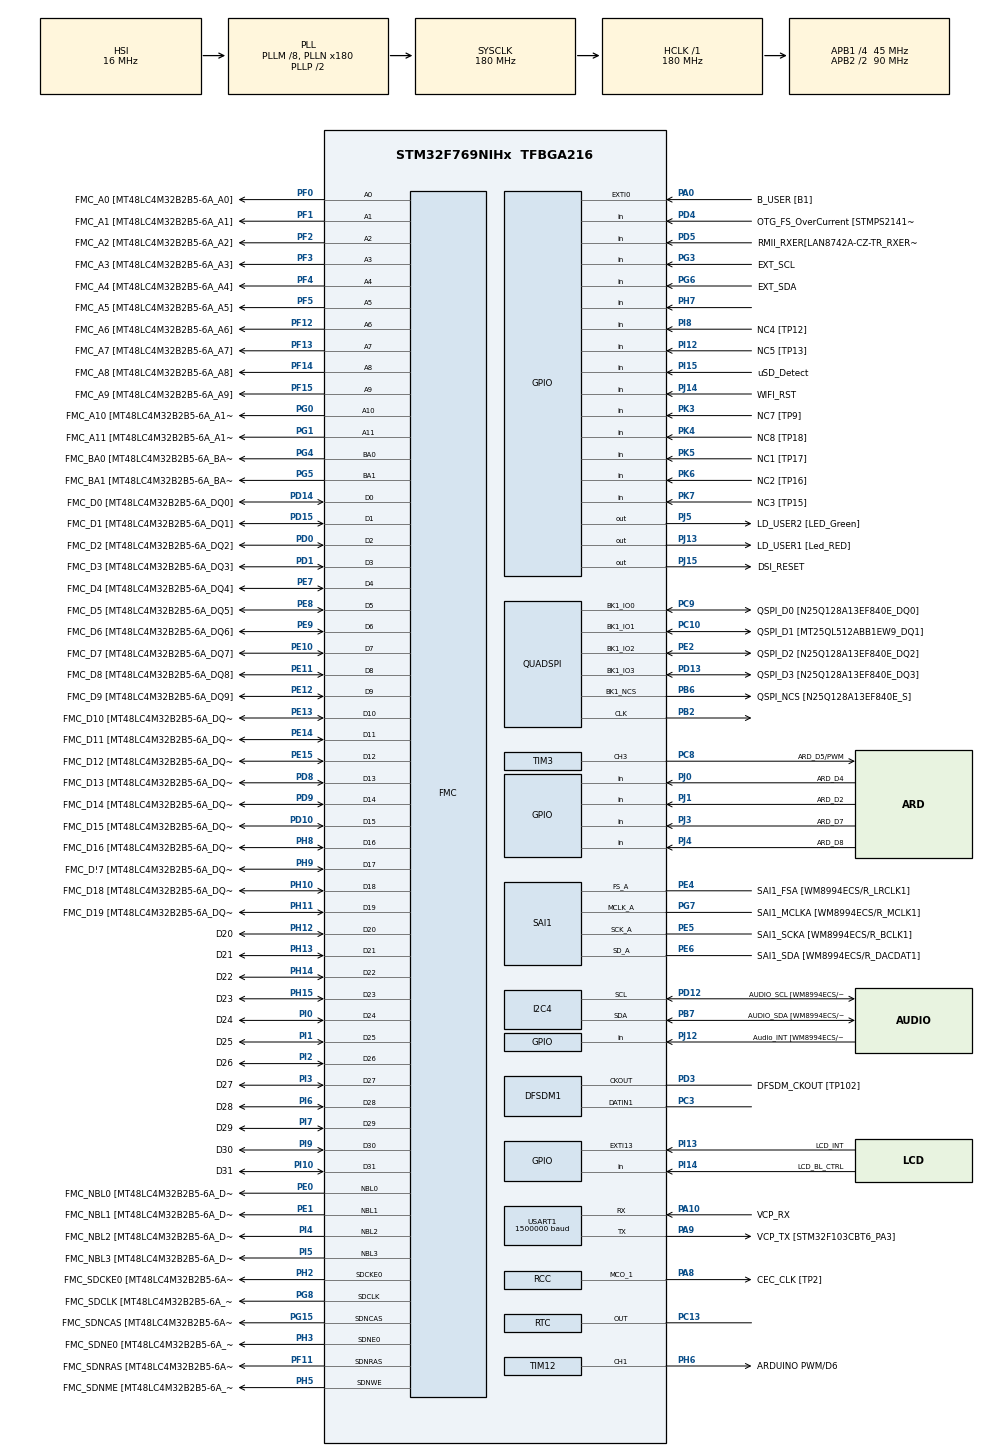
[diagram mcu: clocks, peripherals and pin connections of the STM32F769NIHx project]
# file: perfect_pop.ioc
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CORTEX_M7.AccessPermission-Cortex_Memory_Protection_Unit_Region0_Settings=MPU_REGION_FULL_ACCESS
CORTEX_M7.BaseAddress-Cortex_Memory_Protection_Unit_Region0_Settings=0xC0000000
CORTEX_M7.DisableExec-Cortex_Memory_Protection_Unit_Region0_Settings=MPU_INSTRUCTION_ACCESS_DISABLE
CORTEX_M7.Enable-Cortex_Memory_Protection_Unit_Region0_Settings=MPU_REGION_ENABLE
CORTEX_M7.MPU_Control=MPU_HFNMI_PRIVDEF
CORTEX_M7.Size-Cortex_Memory_Protection_Unit_Region0_Settings=MPU_REGION_SIZE_2MB
DFSDM1.Divider=75
DFSDM1.DmaMode_inj_FIL0=ENABLE
DFSDM1.DmaMode_reg_FIL0=ENABLE
DFSDM1.FastMode_reg_FIL0=ENABLE
DFSDM1.FilterOrder_CH0=DFSDM_CHANNEL_FASTSINC_ORDER
DFSDM1.Filter_injChannel0_FIL0=DFSDM_CHANNEL_0
DFSDM1.Filter_regChannel_FIL0=DFSDM_CHANNEL_0
DFSDM1.Fosr_FIL0=50
DFSDM1.Iosr_FIL0=1
DFSDM1.Offset_CH0=0
DFSDM1.Oversampling_CH0=1
DFSDM1.RightBitShift_CH0=0
DFSDM1.ScanMode_inj_FIL0=ENABLE
DFSDM1.Selection=DFSDM_CHANNEL_OUTPUT_CLOCK_SYSTEM
DFSDM1.SincOrder_FIL0=DFSDM_FILTER_SINC3_ORDER
DFSDM1.Trigger_inj_FIL0=DFSDM_FILTER_SW_TRIGGER
DFSDM1.Type_spi_CH0=DFSDM_CHANNEL_SPI_FALLING
DSIHOST.CommandSize=800
DSIHOST.NumberOfLanes=DSI_TWO_DATA_LANES
DSIHOST.StopWaitTime=10
DSIHOST_CKN.GPIO_Label=DSI_CK_N
DSIHOST_CKN.Mode=DSIHost_Adapted
DSIHOST_CKN.Signal=DSIHOST_CKN
DSIHOST_CKP.GPIO_Label=DSI_CK_P
DSIHOST_CKP.Mode=DSIHost_Adapted
DSIHOST_CKP.Signal=DSIHOST_CKP
DSIHOST_D0N.GPIO_Label=DSI_D0_N
DSIHOST_D0N.Mode=DSIHost_Adapted
DSIHOST_D0N.Signal=DSIHOST_D0N
DSIHOST_D0P.GPIO_Label=DSI_D0_p
DSIHOST_D0P.Mode=DSIHost_Adapted
DSIHOST_D0P.Signal=DSIHOST_D0P
DSIHOST_D1N.GPIO_Label=DSI_D1_N
DSIHOST_D1N.Mode=DSIHost_Adapted
DSIHOST_D1N.Signal=DSIHOST_D1N
DSIHOST_D1P.GPIO_Label=DSI_D1_P
DSIHOST_D1P.Mode=DSIHost_Adapted
DSIHOST_D1P.Signal=DSIHOST_D1P
Dma.DFSDM1_FLT0.0.Direction=DMA_PERIPH_TO_MEMORY
Dma.DFSDM1_FLT0.0.FIFOMode=DMA_FIFOMODE_DISABLE
Dma.DFSDM1_FLT0.0.Instance=DMA2_Stream0
Dma.DFSDM1_FLT0.0.MemDataAlignment=DMA_MDATAALIGN_WORD
Dma.DFSDM1_FLT0.0.MemInc=DMA_MINC_ENABLE
Dma.DFSDM1_FLT0.0.Mode=DMA_CIRCULAR
Dma.DFSDM1_FLT0.0.PeriphDataAlignment=DMA_PDATAALIGN_WORD
Dma.DFSDM1_FLT0.0.PeriphInc=DMA_PINC_DISABLE
Dma.DFSDM1_FLT0.0.Priority=DMA_PRIORITY_MEDIUM
Dma.Request0=DFSDM1_FLT0
Dma.Request1=USART1_RX
Dma.Request2=USART1_TX
Dma.Request3=SAI1_A
Dma.SAI1_A.3.Direction=DMA_MEMORY_TO_PERIPH
Dma.SAI1_A.3.FIFOMode=DMA_FIFOMODE_DISABLE
Dma.SAI1_A.3.Instance=DMA2_Stream1
Dma.SAI1_A.3.MemDataAlignment=DMA_MDATAALIGN_HALFWORD
Dma.SAI1_A.3.MemInc=DMA_MINC_DISABLE
Dma.SAI1_A.3.Mode=DMA_CIRCULAR
Dma.SAI1_A.3.PeriphDataAlignment=DMA_PDATAALIGN_HALFWORD
Dma.SAI1_A.3.PeriphInc=DMA_PINC_DISABLE
Dma.SAI1_A.3.Priority=DMA_PRIORITY_HIGH
Dma.USART1_RX.1.Direction=DMA_PERIPH_TO_MEMORY
Dma.USART1_RX.1.FIFOMode=DMA_FIFOMODE_DISABLE
Dma.USART1_RX.1.Instance=DMA2_Stream2
Dma.USART1_RX.1.MemDataAlignment=DMA_MDATAALIGN_BYTE
Dma.USART1_RX.1.MemInc=DMA_MINC_ENABLE
Dma.USART1_RX.1.Mode=DMA_CIRCULAR
Dma.USART1_RX.1.PeriphDataAlignment=DMA_PDATAALIGN_BYTE
Dma.USART1_RX.1.PeriphInc=DMA_PINC_DISABLE
Dma.USART1_RX.1.Priority=DMA_PRIORITY_LOW
Dma.USART1_TX.2.Direction=DMA_MEMORY_TO_PERIPH
Dma.USART1_TX.2.FIFOMode=DMA_FIFOMODE_DISABLE
Dma.USART1_TX.2.Instance=DMA2_Stream7
Dma.USART1_TX.2.MemDataAlignment=DMA_MDATAALIGN_BYTE
Dma.USART1_TX.2.MemInc=DMA_MINC_ENABLE
Dma.USART1_TX.2.Mode=DMA_NORMAL
Dma.USART1_TX.2.PeriphDataAlignment=DMA_PDATAALIGN_BYTE
Dma.USART1_TX.2.PeriphInc=DMA_PINC_DISABLE
Dma.USART1_TX.2.Priority=DMA_PRIORITY_LOW
FMC.CASLatency1=FMC_SDRAM_CAS_LATENCY_3
FMC.ExitSelfRefreshDelay1=7
FMC.LoadToActiveDelay1=2
FMC.RPDelay1=2
FMC.RPDelay2=2
FMC.ReadBurst1=FMC_SDRAM_RBURST_ENABLE
FMC.ReadBurst2=FMC_SDRAM_RBURST_ENABLE
FMC.RowCycleDelay1=7
FMC.RowCycleDelay2=7
FMC.SDClockPeriod1=FMC_SDRAM_CLOCK_PERIOD_2
FMC.SDClockPeriod2=FMC_SDRAM_CLOCK_PERIOD_2
FMC.SelfRefreshTime1=4
FMC.WriteRecoveryTime1=2
FREERTOS.Tasks01=defaultTask,24,128,StartDefaultTask,Default,NULL,Dynamic,NULL,NULL;audio_producer,31,1280,start_audio_producer,Default,NULL,Dynamic,NULL,NULL;uart_handler,8,128,start_uart_handler,Default,NULL,Dynamic,NULL,NULL;audio_filter,31,1280,start_audio_filter,Default,NULL,Dynamic,NULL,NULL;display_control,23,2048,start_display_control,Default,NULL,Dynamic,NULL,NULL
FREERTOS.configCHECK_FOR_STACK_OVERFLOW=2
FREERTOS.configTOTAL_HEAP_SIZE=24576
FREERTOS.configUSE_MALLOC_FAILED_HOOK=1
FREERTOS.configUSE_NEWLIB_REENTRANT=1
I2C4.Timing=0xC0000E12
LTDC.ActiveW=800
LTDC.Alpha_L0=255
LTDC.BlendingFactor1_L0=LTDC_BLENDING_FACTOR1_PAxCA
LTDC.BlendingFactor2_L0=LTDC_BLENDING_FACTOR2_PAxCA
LTDC.FBStartAdress_L0=0xC0000000
LTDC.HBP=1
LTDC.HFP=1
LTDC.HSync=1
LTDC.ImageHeight_L0=480
LTDC.ImageWidth_L0=800
LTDC.Layers=0
LTDC.PixelFormat_L0=LTDC_PIXEL_FORMAT_ARGB8888
LTDC.VBP=1
LTDC.VFP=1
LTDC.VSync=1
LTDC.WindowX1_L0=800
LTDC.WindowY1_L0=480
Mcu.Family=STM32F7
Mcu.Name=STM32F769NIHx
Mcu.Package=TFBGA216
NVIC.DFSDM1_FLT0_IRQn=true\:5\:0\:false\:false\:true\:true\:true\:true\:true
NVIC.DMA2_Stream0_IRQn=true\:5\:0\:false\:false\:true\:false\:false\:true\:true
NVIC.DMA2_Stream1_IRQn=true\:5\:0\:false\:false\:true\:true\:false\:true\:true
NVIC.DMA2_Stream2_IRQn=true\:5\:0\:false\:false\:true\:true\:false\:true\:true
NVIC.DMA2_Stream7_IRQn=true\:5\:0\:false\:false\:true\:true\:false\:true\:true
NVIC.I2C4_ER_IRQn=true\:5\:0\:false\:false\:true\:true\:true\:true\:true
NVIC.I2C4_EV_IRQn=true\:5\:0\:false\:false\:true\:true\:true\:true\:true
NVIC.LTDC_IRQn=true\:5\:0\:false\:false\:true\:true\:true\:true\:true
NVIC.PriorityGroup=NVIC_PRIORITYGROUP_4
NVIC.SAI1_IRQn=true\:5\:0\:false\:false\:true\:true\:true\:true\:true
NVIC.TIM6_DAC_IRQn=true\:15\:0\:false\:false\:true\:false\:false\:true\:true
NVIC.TimeBase=TIM6_DAC_IRQn
NVIC.TimeBaseIP=TIM6
NVIC.USART1_IRQn=true\:5\:0\:false\:false\:true\:true\:true\:true\:true
PA0/WKUP.GPIO_Label=B_USER [B1]
PA0/WKUP.Signal=GPXTI0
PA1.GPIO_Label=RMII_REF_CLK [LAN8742A-CZ-TR_REFCLK0]
PA1.Signal=ETH_REF_CLK
PA10.GPIO_Label=VCP_RX 
PA10.Mode=Asynchronous
PA10.Signal=USART1_RX
PA11.GPIO_Label=SPI2_NSS
PA11.Signal=SPI2_NSS
PA12.GPIO_Label=ARD_D13/SCK
PA12.GPIO_Mode=GPIO_MODE_AF_PP
PA12.GPIO_PuPd=GPIO_NOPULL
PA12.GPIO_Speed=GPIO_SPEED_FREQ_LOW
PA12.Signal=SPI2_SCK
PA13.GPIO_Label=SWDIO
PA13.Mode=Serial_Wire
PA13.Signal=SYS_JTMS-SWDIO
PA14.GPIO_Label=SWCLK
PA14.Mode=Serial_Wire
PA14.Signal=SYS_JTCK-SWCLK
PA15.GPIO_Label=CEC
PA15.Signal=CEC
PA2.GPIO_Label=RMII_MDIO [LAN8742A-CZ-TR_MDIO]
PA2.Signal=ETH_MDIO
PA3.GPIO_Label=ULPI_D0 [USB3320C-EZK_D0]
PA3.Signal=USB_OTG_HS_ULPI_D0
PA4.GPIO_Label=ARD_A1
PA4.Signal=ADCx_IN4
PA5.GPIO_Label=ULPI_CLK [USB3320C-EZK_CLKOUT]
PA5.Signal=USB_OTG_HS_ULPI_CK
PA6.GPIO_Label=ARD_A0
PA6.Signal=ADCx_IN6
PA7.GPIO_Label=RMII_CRS_DV [LAN8742A-CZ-TR_CRS_DV]
PA7.Signal=ETH_CRS_DV
PA8.GPIO_Label=CEC_CLK [TP2]
PA8.Mode=Clock-out-1
PA8.Signal=RCC_MCO_1
PA9.GPIO_Label=VCP_TX [STM32F103CBT6_PA3]
PA9.GPIO_Mode=GPIO_MODE_AF_PP
PA9.GPIO_PuPd=GPIO_NOPULL
PA9.GPIO_Speed=GPIO_SPEED_FREQ_LOW
PA9.Mode=Asynchronous
PA9.Signal=USART1_TX
PB0.GPIO_Label=ULPI_D1 [USB3320C-EZK_D1]
PB0.Signal=USB_OTG_HS_ULPI_D1
PB1.GPIO_Label=ULPI_D2 [USB3320C-EZK_D2]
PB1.Signal=USB_OTG_HS_ULPI_D2
PB10.GPIO_Label=ULPI_D3 [USB3320C-EZK_D3]
PB10.Signal=USB_OTG_HS_ULPI_D3
PB11.GPIO_Label=ULPI_D4 [USB3320C-EZK_D4]
PB11.Signal=USB_OTG_HS_ULPI_D4
PB12.GPIO_Label=ULPI_D5 [USB3320C-EZK_D5]
PB12.Signal=USB_OTG_HS_ULPI_D5
PB13.GPIO_Label=ULPI_D6 [USB3320C-EZK_D6]
PB13.Signal=USB_OTG_HS_ULPI_D6
PB14.GPIO_Label=ARDUINO MISO/D12
PB14.GPIO_Mode=GPIO_MODE_AF_PP
PB14.GPIO_PuPd=GPIO_NOPULL
PB14.GPIO_Speed=GPIO_SPEED_FREQ_LOW
PB14.Signal=SPI2_MISO
PB15.GPIO_Label=ARDUINO MOSI/PWM/D11
PB15.GPIO_Mode=GPIO_MODE_AF_PP
PB15.GPIO_PuPd=GPIO_NOPULL
PB15.GPIO_Speed=GPIO_SPEED_FREQ_LOW
PB15.Signal=SPI2_MOSI
PB2.Mode=Single Bank 1
PB2.Signal=QUADSPI_CLK
PB3.GPIO_Label=uSD_D2
PB3.Signal=SDMMC2_D2
PB4.GPIO_Label=uSD_D3
PB4.Signal=SDMMC2_D3
PB5.GPIO_Label=ULPI_D7 [USB3320C-EZK_D7]
PB5.Signal=USB_OTG_HS_ULPI_D7
PB6.GPIO_Label=QSPI_NCS [N25Q128A13EF840E_S]
PB6.Mode=Single Bank 1
PB6.Signal=QUADSPI_BK1_NCS
PB7.GPIO_Label=AUDIO_SDA [WM8994ECS/R_SDA]
PB7.GPIO_Pu=GPIO_PULLUP
PB7.Mode=I2C
PB7.Signal=I2C4_SDA
PB8.GPIO_Label=ARDUINO SCL/D15
PB8.GPIO_Mode=GPIO_MODE_AF_OD
PB8.GPIO_Pu=GPIO_PULLUP
PB8.GPIO_PuPd=GPIO_NOPULL
PB8.GPIO_Speed=GPIO_SPEED_FREQ_LOW
PB8.Signal=I2C1_SCL
PB9.GPIO_Label=ARDUINO SDA/D14
PB9.GPIO_Mode=GPIO_MODE_AF_OD
PB9.GPIO_Pu=GPIO_PULLUP
PB9.GPIO_PuPd=GPIO_NOPULL
PB9.GPIO_Speed=GPIO_SPEED_FREQ_LOW
PB9.Signal=I2C1_SDA
PC0.GPIO_Label=ULPI_STP [USB3320C-EZK_STP]
PC0.Signal=USB_OTG_HS_ULPI_STP
PC1.GPIO_Label=RMII_MDC [LAN8742A-CZ-TR_MDC]
PC1.Signal=ETH_MDC
PC10.GPIO_Label=QSPI_D1 [MT25QL512ABB1EW9_DQ1]
PC10.Mode=Single Bank 1
PC10.Signal=QUADSPI_BK1_IO1
PC11.GPIO_Label=DFSDM_DATIN5 [TP5]
PC11.Signal=S_DATAIN5DFSDM1
PC12.GPIO_Label=WIFI_RX
PC12.Signal=UART5_TX
PC13.Mode=AlarmA_RoutedAF
PC13.Signal=RTC_OUT
PC14/OSC32_IN.GPIO_Label=RCC_OSC32_IN
PC14/OSC32_IN.Mode=LSE-External-Oscillator
PC14/OSC32_IN.Signal=RCC_OSC32_IN
PC15/OSC32_OUT.GPIO_Label=RCC_OSC32_OUT
PC15/OSC32_OUT.Mode=LSE-External-Oscillator
PC15/OSC32_OUT.Signal=RCC_OSC32_OUT
PC2.GPIO_Label=ARD_A2
PC2.Signal=ADCx_IN12
PC3.Signal=S_DATAIN1DFSDM1
PC4.GPIO_Label=RMII_RXD0 [LAN8742A-CZ-TR_RXD0]
PC4.Signal=ETH_RXD0
PC5.GPIO_Label=RMII_RXD1 [LAN8742A-CZ-TR_RXD1]
PC5.Signal=ETH_RXD1
PC6.GPIO_Label=ARDUINO TX/D1
PC6.Signal=USART6_TX
PC7.GPIO_Label=ARD_D0/RX
PC7.Signal=USART6_RX
PC8.GPIO_Label=ARD_D5/PWM
PC8.Signal=S_TIM3_CH3
PC9.GPIO_Label=QSPI_D0 [N25Q128A13EF840E_DQ0]
PC9.Mode=Single Bank 1
PC9.Signal=QUADSPI_BK1_IO0
PD0.GPIO_Label=FMC_D2 [MT48LC4M32B2B5-6A_DQ2]
PD0.Signal=FMC_D2_DA2
PD1.GPIO_Label=FMC_D3 [MT48LC4M32B2B5-6A_DQ3]
PD1.Signal=FMC_D3_DA3
PD10.GPIO_Label=FMC_D15 [MT48LC4M32B2B5-6A_DQ15]
PD10.Signal=FMC_D15_DA15
PD11.GPIO_Label=SPDIF_TX [TP20]
PD11.Signal=SAI2_SD_A
PD12.GPIO_Label=AUDIO_SCL [WM8994ECS/R_SCLK]
PD12.GPIO_Pu=GPIO_PULLUP
PD12.Mode=I2C
PD12.Signal=I2C4_SCL
PD13.GPIO_Label=QSPI_D3 [N25Q128A13EF840E_DQ3]
PD13.Mode=Single Bank 1
PD13.Signal=QUADSPI_BK1_IO3
PD14.GPIO_Label=FMC_D0 [MT48LC4M32B2B5-6A_DQ0]
PD14.Signal=FMC_D0_DA0
PD15.GPIO_Label=FMC_D1 [MT48LC4M32B2B5-6A_DQ1]
PD15.Signal=FMC_D1_DA1
PD2.GPIO_Label=WIFI_TX
PD2.Signal=UART5_RX
PD3.GPIO_Label=DFSDM_CKOUT [TP102]
PD3.Signal=S_CKOUTDFSDM1
PD4.GPIO_Label=OTG_FS_OverCurrent [STMPS2141STR_Fault]
PD4.Signal=GPIO_Input
PD5.GPIO_Label=RMII_RXER[LAN8742A-CZ-TR_RXERR]
PD5.Signal=GPIO_Input
PD6.GPIO_Label=uSD_CLK
PD6.Signal=SDMMC2_CK
PD7.GPIO_Label=uSD_CMD
PD7.Signal=SDMMC2_CMD
PD8.GPIO_Label=FMC_D13 [MT48LC4M32B2B5-6A_DQ13]
PD8.Signal=FMC_D13_DA13
PD9.GPIO_Label=FMC_D14 [MT48LC4M32B2B5-6A_DQ14]
PD9.Signal=FMC_D14_DA14
PE0.GPIO_Label=FMC_NBL0 [MT48LC4M32B2B5-6A_DQM0]
PE0.Signal=FMC_NBL0
PE1.GPIO_Label=FMC_NBL1 [MT48LC4M32B2B5-6A_DQM1]
PE1.Signal=FMC_NBL1
PE10.GPIO_Label=FMC_D7 [MT48LC4M32B2B5-6A_DQ7]
PE10.Signal=FMC_D7_DA7
PE11.GPIO_Label=FMC_D8 [MT48LC4M32B2B5-6A_DQ8]
PE11.Signal=FMC_D8_DA8
PE12.GPIO_Label=FMC_D9 [MT48LC4M32B2B5-6A_DQ9]
PE12.Signal=FMC_D9_DA9
PE13.GPIO_Label=FMC_D10 [MT48LC4M32B2B5-6A_DQ10]
PE13.Signal=FMC_D10_DA10
PE14.GPIO_Label=FMC_D11 [MT48LC4M32B2B5-6A_DQ11]
PE14.Signal=FMC_D11_DA11
PE15.GPIO_Label=FMC_D12 [MT48LC4M32B2B5-6A_DQ12]
PE15.Signal=FMC_D12_DA12
PE2.GPIO_Label=QSPI_D2 [N25Q128A13EF840E_DQ2]
PE2.Mode=Single Bank 1
PE2.Signal=QUADSPI_BK1_IO2
PE3.GPIO_Label=SAI1_SDB [WM8994ECS/R_ADCDAT1]
PE3.Signal=SAI1_SD_B
PE4.GPIO_Label=SAI1_FSA [WM8994ECS/R_LRCLK1]
PE4.Mode=SAI_A_MasterWithClock
PE4.Signal=SAI1_FS_A
PE5.GPIO_Label=SAI1_SCKA [WM8994ECS/R_BCLK1]
PE5.Mode=SAI_A_MasterWithClock
PE5.Signal=SAI1_SCK_A
PE6.GPIO_Label=SAI1_SDA [WM8994ECS/R_DACDAT1]
PE6.Mode=SAI_A_MasterWithClock
PE6.Signal=SAI1_SD_A
PE7.GPIO_Label=FMC_D4 [MT48LC4M32B2B5-6A_DQ4]
PE7.Signal=FMC_D4_DA4
PE8.GPIO_Label=FMC_D5 [MT48LC4M32B2B5-6A_DQ5]
PE8.Signal=FMC_D5_DA5
PE9.GPIO_Label=FMC_D6 [MT48LC4M32B2B5-6A_DQ6]
PE9.Signal=FMC_D6_DA6
PF0.GPIO_Label=FMC_A0 [MT48LC4M32B2B5-6A_A0]
PF0.Signal=FMC_A0
PF1.GPIO_Label=FMC_A1 [MT48LC4M32B2B5-6A_A1]
PF1.Signal=FMC_A1
PF10.GPIO_Label=ARDUINO A1
PF10.GPIO_Mode=GPIO_MODE_ANALOG
PF10.GPIO_PuPd=GPIO_NOPULL
PF10.Signal=ADC3_IN8
PF11.GPIO_Label=FMC_SDNRAS [MT48LC4M32B2B5-6A_RAS]
PF11.Signal=FMC_SDNRAS
PF12.GPIO_Label=FMC_A6 [MT48LC4M32B2B5-6A_A6]
PF12.Signal=FMC_A6
PF13.GPIO_Label=FMC_A7 [MT48LC4M32B2B5-6A_A7]
PF13.Signal=FMC_A7
PF14.GPIO_Label=FMC_A8 [MT48LC4M32B2B5-6A_A8]
PF14.Signal=FMC_A8
PF15.GPIO_Label=FMC_A9 [MT48LC4M32B2B5-6A_A9]
PF15.Signal=FMC_A9
PF2.GPIO_Label=FMC_A2 [MT48LC4M32B2B5-6A_A2]
PF2.Signal=FMC_A2
PF3.GPIO_Label=FMC_A3 [MT48LC4M32B2B5-6A_A3]
PF3.Signal=FMC_A3
PF4.GPIO_Label=FMC_A4 [MT48LC4M32B2B5-6A_A4]
PF4.Signal=FMC_A4
PF5.GPIO_Label=FMC_A5 [MT48LC4M32B2B5-6A_A5]
PF5.Signal=FMC_A5
PF6.GPIO_Label=ARD_D3/PWM
PF6.Signal=S_TIM10_CH1
PF7.GPIO_Label=ARD_D6/PWM
PF7.Signal=S_TIM11_CH1
PF8.GPIO_Label=ARDUINO A3
PF8.GPIO_Mode=GPIO_MODE_ANALOG
PF8.GPIO_PuPd=GPIO_NOPULL
PF8.Signal=ADC3_IN6
PF9.GPIO_Label=ARDUINO A2
PF9.GPIO_Mode=GPIO_MODE_ANALOG
PF9.GPIO_PuPd=GPIO_NOPULL
PF9.Signal=ADC3_IN7
PG0.GPIO_Label=FMC_A10 [MT48LC4M32B2B5-6A_A10]
PG0.Signal=FMC_A10
PG1.GPIO_Label=FMC_A11 [MT48LC4M32B2B5-6A_A11]
PG1.Signal=FMC_A11
PG10.GPIO_Label=uSD_D1
PG10.Signal=SDMMC2_D1
PG11.GPIO_Label=RMII_TX_EN [LAN8742A-CZ-TR_TXEN]
PG11.Signal=ETH_TX_EN
PG12.GPIO_Label=SPDIF_RX [74LVC1G04SE_4]
PG12.Signal=SPDIFRX_IN1
PG13.GPIO_Label=RMII_TXD0 [LAN8742A-CZ-TR_TXD0]
PG13.Signal=ETH_TXD0
PG14.GPIO_Label=RMII_TXD1 [LAN8742A-CZ-TR_TXD1]
PG14.Signal=ETH_TXD1
PG15.GPIO_Label=FMC_SDNCAS [MT48LC4M32B2B5-6A_CAS]
PG15.Signal=FMC_SDNCAS
PG2.GPIO_Label=FMC_A12
PG2.Signal=FMC_A12
PG3.GPIO_Label=EXT_SCL
PG3.Signal=GPIO_Input
PG4.GPIO_Label=FMC_BA0 [MT48LC4M32B2B5-6A_BA0]
PG4.Signal=FMC_A14_BA0
PG5.GPIO_Label=FMC_BA1 [MT48LC4M32B2B5-6A_BA1]
PG5.Signal=FMC_A15_BA1
PG6.GPIO_Label=EXT_SDA
PG6.Signal=GPIO_Input
PG7.GPIO_Label=SAI1_MCLKA [WM8994ECS/R_MCLK1]
PG7.Mode=SAI_A_MasterWithClock
PG7.Signal=SAI1_MCLK_A
PG8.GPIO_Label=FMC_SDCLK [MT48LC4M32B2B5-6A_CLK]
PG8.Signal=FMC_SDCLK
PG9.GPIO_Label=uSD_D0
PG9.Signal=SDMMC2_D0
PH0/OSC_IN.GPIO_Label=OSC_25M [NZ2520SB-25.00M_OUT]
PH0/OSC_IN.Mode=HSE-External-Oscillator
PH0/OSC_IN.Signal=RCC_OSC_IN
PH1/OSC_OUT.Mode=HSE-External-Oscillator
PH1/OSC_OUT.Signal=RCC_OSC_OUT
PH10.GPIO_Label=FMC_D18 [MT48LC4M32B2B5-6A_DQ18]
PH10.Signal=FMC_D18
PH11.GPIO_Label=FMC_D19 [MT48LC4M32B2B5-6A_DQ19]
PH11.Signal=FMC_D19
PH12.GPIO_Label=D20
PH12.Signal=FMC_D20
PH13.GPIO_Label=D21
PH13.Signal=FMC_D21
PH14.GPIO_Label=D22
PH14.Signal=FMC_D22
PH15.GPIO_Label=D23
PH15.Signal=FMC_D23
PH2.GPIO_Label=FMC_SDCKE0 [MT48LC4M32B2B5-6A_CKE]
PH2.Mode=SdramChipSelect1_1
PH2.Signal=FMC_SDCKE0
PH3.GPIO_Label=FMC_SDNE0 [MT48LC4M32B2B5-6A_CS]
PH3.Mode=SdramChipSelect1_1
PH3.Signal=FMC_SDNE0
PH4.GPIO_Label=ULPI_NXT [USB3320C-EZK_NXT]
PH4.Signal=USB_OTG_HS_ULPI_NXT
PH5.GPIO_Label=FMC_SDNME [MT48LC4M32B2B5-6A_WE]
PH5.Signal=FMC_SDNWE
PH6.GPIO_Label=ARDUINO PWM/D6
PH6.Signal=S_TIM12_CH1
PH7.Signal=GPIO_Input
PH8.GPIO_Label=FMC_D16 [MT48LC4M32B2B5-6A_DQ16]
PH8.Signal=FMC_D16
PH9.GPIO_Label=FMC_D\!7 [MT48LC4M32B2B5-6A_DQ17]
PH9.Signal=FMC_D17
PI0.GPIO_Label=D24
PI0.Signal=FMC_D24
PI1.GPIO_Label=D25
PI1.Signal=FMC_D25
PI10.GPIO_Label=D31
PI10.Signal=FMC_D31
PI11.GPIO_Label=ULPI_DIR [USB3320C-EZK_DIR]
PI11.Signal=USB_OTG_HS_ULPI_DIR
PI12.GPIO_Label=NC5 [TP13]
PI12.Signal=GPIO_Input
PI13.GPIO_Label=LCD_INT
PI13.GPIO_ModeDefaultEXTI=GPIO_MODE_EVT_RISING
PI13.Signal=GPXTI13
PI14.GPIO_Label=LCD_BL_CTRL
PI14.Signal=GPIO_Input
PI15.GPIO_Label=uSD_Detect
PI15.Signal=GPIO_Input
PI2.GPIO_Label=D26
PI2.Signal=FMC_D26
PI3.GPIO_Label=D27
PI3.Signal=FMC_D27
PI4.GPIO_Label=FMC_NBL2 [MT48LC4M32B2B5-6A_DQM2]
PI4.Signal=FMC_NBL2
PI5.GPIO_Label=FMC_NBL3 [MT48LC4M32B2B5-6A_DQM3]
PI5.Signal=FMC_NBL3
PI6.GPIO_Label=D28
PI6.Signal=FMC_D28
PI7.GPIO_Label=D29
PI7.Signal=FMC_D29
PI8.GPIO_Label=NC4 [TP12]
PI8.Signal=GPIO_Input
PI9.GPIO_Label=D30
PI9.Signal=FMC_D30
PJ0.GPIO_Label=ARD_D4
PJ0.Signal=GPIO_Input
PJ1.GPIO_Label=ARD_D2
PJ1.Signal=GPIO_Input
PJ12.GPIO_Label=Audio_INT [WM8994ECS/R_GPIO1]
PJ12.Signal=GPIO_Input
PJ13.GPIO_Label=LD_USER1 [Led_RED]
PJ13.Signal=GPIO_Output
PJ14.GPIO_Label=WIFI_RST
PJ14.Signal=GPIO_Input
PJ15.GPIO_Label=DSI_RESET
PJ15.Signal=GPIO_Output
PJ2.GPIO_Label=DSIHOST_TE
PJ2.Signal=DSIHOST_TE
PJ3.GPIO_Label=ARD_D7
PJ3.Signal=GPIO_Input
PJ4.GPIO_Label=ARD_D8
PJ4.Signal=GPIO_Input
PJ5.GPIO_Label=LD_USER2 [LED_Green]
PJ5.Signal=GPIO_Output
PK3.GPIO_Label=NC7 [TP9]
PK3.Signal=GPIO_Input
PK4.GPIO_Label=NC8 [TP18]
PK4.Signal=GPIO_Input
PK5.GPIO_Label=NC1 [TP17]
PK5.Signal=GPIO_Input
PK6.GPIO_Label=NC2 [TP16]
PK6.Signal=GPIO_Input
PK7.GPIO_Label=NC3 [TP15]
PK7.Signal=GPIO_Input
ProjectManager.HeapSize=0x200
ProjectManager.StackSize=0x400
ProjectManager.TargetToolchain=STM32CubeIDE
QUADSPI.ChipSelectHighTime=QSPI_CS_HIGH_TIME_4_CYCLE
QUADSPI.ClockPrescaler=1
QUADSPI.FifoThreshold=16
QUADSPI.FlashSize=26
QUADSPI.SampleShifting=QSPI_SAMPLE_SHIFTING_HALFCYCLE
RCC.AHBFreq_Value=180000000
RCC.APB1CLKDivider=RCC_HCLK_DIV4
RCC.APB1Freq_Value=45000000
RCC.APB1TimFreq_Value=90000000
RCC.APB2CLKDivider=RCC_HCLK_DIV2
RCC.APB2Freq_Value=90000000
RCC.APB2TimFreq_Value=180000000
RCC.CortexFreq_Value=180000000
RCC.DFSDMSelection=RCC_DFSDM1CLKSOURCE_SYSCLK
RCC.HCLKFreq_Value=180000000
RCC.HSE_VALUE=25000000
RCC.HSI_VALUE=16000000
RCC.PLL48CLockSelection=RCC_CLK48SOURCE_PLLSAIP
RCC.PLLM=8
RCC.PLLN=180
RCC.PLLQ=4
RCC.PLLSAIN=96
RCC.PLLSAIP=RCC_PLLSAIP_DIV4
RCC.PLLSAIQ=3
RCC.PLLSAIR=3
RCC.SDMMC2ClockSelection=RCC_SDMMC2CLKSOURCE_CLK48
RCC.SYSCLKFreq_VALUE=180000000
RCC.SYSCLKSource=RCC_SYSCLKSOURCE_PLLCLK
RCC.USBFreq_Value=48000000
RCC.VCOOutputFreq_Value=360000000
RTC.Alarm-AlarmA_RoutedAF=RTC_ALARM_A
RTC.Alarm_B-Alarm\ B=RTC_ALARM_B
SAI1.ActiveFrameLength-SAI_A_MasterWithClock=16
SAI1.AudioFrequency-SAI_A_MasterWithClock=SAI_AUDIO_FREQUENCY_44K
SAI1.DataSize-SAI_A_MasterWithClock=SAI_DATASIZE_16
SAI1.ErrorAudioFreq-SAI_A_MasterWithClock=-5.51 %
SAI1.FSDefinition-SAI_A_MasterWithClock=SAI_FS_CHANNEL_IDENTIFICATION
SAI1.FrameLength-SAI_A_MasterWithClock=32
SAI1.Instance-SAI_A_MasterWithClock=SAI$Index_Block_A
SAI1.MClockEnable-SAI_A_MasterWithClock=SAI_MASTERCLOCK_ENABLE
SAI1.RealAudioFreq-SAI_A_MasterWithClock=41.666 KHz
SAI1.SlotActive-SAI_A_MasterWithClock=0x00000003
SAI1.SlotNumber-SAI_A_MasterWithClock=2
SAI1.SlotSize-SAI_A_MasterWithClock=SAI_SLOTSIZE_DATASIZE
SAI1.VirtualMode-SAI_A_MasterWithClock=VM_MASTER
SAI1.VirtualSlotActive-SAI_A_MasterWithClock=SAI_SLOT_USERSETTING
SAI1.VirtualSlotActive0-SAI_A_MasterWithClock=true
SAI1.VirtualSlotActive1-SAI_A_MasterWithClock=true
SH.ADCx_IN12.0=ADC1_IN12
SH.ADCx_IN4.0=ADC1_IN4
SH.ADCx_IN6.0=ADC1_IN6
SH.FMC_A0.0=FMC_A0,12b-sda1
SH.FMC_A1.0=FMC_A1,12b-sda1
SH.FMC_A10.0=FMC_A10,12b-sda1
SH.FMC_A11.0=FMC_A11,12b-sda1
SH.FMC_A12.0=FMC_A12
SH.FMC_A14_BA0.0=FMC_BA0,FourSdramBanks1
SH.FMC_A15_BA1.0=FMC_BA1,FourSdramBanks1
SH.FMC_A2.0=FMC_A2,12b-sda1
SH.FMC_A3.0=FMC_A3,12b-sda1
SH.FMC_A4.0=FMC_A4,12b-sda1
SH.FMC_A5.0=FMC_A5,12b-sda1
SH.FMC_A6.0=FMC_A6,12b-sda1
SH.FMC_A7.0=FMC_A7,12b-sda1
SH.FMC_A8.0=FMC_A8,12b-sda1
SH.FMC_A9.0=FMC_A9,12b-sda1
SH.FMC_D0_DA0.0=FMC_D0,sd-32b-d1
SH.FMC_D10_DA10.0=FMC_D10,sd-32b-d1
SH.FMC_D11_DA11.0=FMC_D11,sd-32b-d1
SH.FMC_D12_DA12.0=FMC_D12,sd-32b-d1
SH.FMC_D13_DA13.0=FMC_D13,sd-32b-d1
SH.FMC_D14_DA14.0=FMC_D14,sd-32b-d1
SH.FMC_D15_DA15.0=FMC_D15,sd-32b-d1
SH.FMC_D16.0=FMC_D16,sd-32b-d1
SH.FMC_D17.0=FMC_D17,sd-32b-d1
SH.FMC_D18.0=FMC_D18,sd-32b-d1
SH.FMC_D19.0=FMC_D19,sd-32b-d1
SH.FMC_D1_DA1.0=FMC_D1,sd-32b-d1
SH.FMC_D20.0=FMC_D20,sd-32b-d1
SH.FMC_D21.0=FMC_D21,sd-32b-d1
SH.FMC_D22.0=FMC_D22,sd-32b-d1
SH.FMC_D23.0=FMC_D23,sd-32b-d1
SH.FMC_D24.0=FMC_D24,sd-32b-d1
SH.FMC_D25.0=FMC_D25,sd-32b-d1
SH.FMC_D26.0=FMC_D26,sd-32b-d1
SH.FMC_D27.0=FMC_D27,sd-32b-d1
SH.FMC_D28.0=FMC_D28,sd-32b-d1
SH.FMC_D29.0=FMC_D29,sd-32b-d1
SH.FMC_D2_DA2.0=FMC_D2,sd-32b-d1
SH.FMC_D30.0=FMC_D30,sd-32b-d1
SH.FMC_D31.0=FMC_D31,sd-32b-d1
SH.FMC_D3_DA3.0=FMC_D3,sd-32b-d1
SH.FMC_D4_DA4.0=FMC_D4,sd-32b-d1
SH.FMC_D5_DA5.0=FMC_D5,sd-32b-d1
SH.FMC_D6_DA6.0=FMC_D6,sd-32b-d1
SH.FMC_D7_DA7.0=FMC_D7,sd-32b-d1
SH.FMC_D8_DA8.0=FMC_D8,sd-32b-d1
SH.FMC_D9_DA9.0=FMC_D9,sd-32b-d1
SH.FMC_NBL0.0=FMC_NBL0,Sd4ByteEnable1
SH.FMC_NBL1.0=FMC_NBL1,Sd4ByteEnable1
SH.FMC_NBL2.0=FMC_NBL2,Sd4ByteEnable1
SH.FMC_NBL3.0=FMC_NBL3,Sd4ByteEnable1
SH.FMC_SDCLK.0=FMC_SDCLK,12b-sda1
SH.FMC_SDNCAS.0=FMC_SDNCAS,12b-sda1
SH.FMC_SDNRAS.0=FMC_SDNRAS,12b-sda1
SH.FMC_SDNWE.0=FMC_SDNWE,12b-sda1
SH.S_CKOUTDFSDM1.0=DFSDM1_CKOUT,PDM_SPI_Input_from_ch01_and_Internal_Clock
SH.S_DATAIN1DFSDM1.0=DFSDM1_DATIN1,PDM_SPI_Input_from_ch01_and_Internal_Clock
SH.S_DATAIN5DFSDM1.0=DFSDM1_DATIN5
SH.S_TIM10_CH1.0=TIM10_CH1
SH.S_TIM11_CH1.0=TIM11_CH1
SH.S_TIM12_CH1.0=TIM12_CH1,PWM Generation1 CH1
SH.S_TIM3_CH3.0=TIM3_CH3,PWM Generation3 CH3
TIM12.Channel-PWM\ Generation1\ CH1=TIM_CHANNEL_1
TIM3.Channel-PWM\ Generation3\ CH3=TIM_CHANNEL_3
USART1.BaudRate=1500000
USART1.VirtualMode-Asynchronous=VM_ASYNC
VP_CRC_VS_CRC.Mode=CRC_Activate
VP_DMA2D_VS_DMA2D.Mode=DMA2D_Activate
VP_FREERTOS_VS_CMSIS_V2.Mode=CMSIS_V2
VP_LTDC_DSIMode.Mode=RGB888
VP_RTC_VS_RTC_Activate.Mode=RTC_Enabled
VP_RTC_VS_RTC_Alarm_B_Intern.Mode=Alarm B
VP_RTC_VS_RTC_Calendar.Mode=RTC_Calendar
VP_SYS_VS_tim6.Mode=TIM6
VP_TIM1_VS_ClockSourceINT.Mode=Internal
board=STM32F769I-DISCO

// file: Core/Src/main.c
/* USER CODE BEGIN Header */
/**
  ******************************************************************************
  * @file           : main.c
  * @brief          : Main program body
  ******************************************************************************
  * @attention
  *
  * Copyright (c) 2026 STMicroelectronics.
  * All rights reserved.
  *
  * This software is licensed under terms that can be found in the LICENSE file
  * in the root directory of this software component.
  * If no LICENSE file comes with this software, it is provided AS-IS.
  *
  ******************************************************************************
  */
/* USER CODE END Header */
#include "main.h"
#include "cmsis_os.h"

/* USER CODE BEGIN Includes */
// #include "pdm2pcm_glo.h"
#include "pp_pdm.h"
#include "pp_display_control.h"
#include "pp_sai.h"
#include "pp_sai_test_tone.h"
#include "pp_uart.h"
#include "pp_dsp.h"
#include "pp_audio_buffer_config.h"
#include <string.h>
#include <sys/types.h>

#include "otm8009a.h"
#include "ft6x06.h"

/* USER CODE END Includes */

/* USER CODE BEGIN PD */

#define SAI_TEST_TONE_ONLY 0U

/* USER CODE END PD */

CRC_HandleTypeDef hcrc;

DFSDM_Filter_HandleTypeDef hdfsdm1_filter0;
DFSDM_Channel_HandleTypeDef hdfsdm1_channel0;
DMA_HandleTypeDef hdma_dfsdm1_flt0;

DMA2D_HandleTypeDef hdma2d;

DSI_HandleTypeDef hdsi;

I2C_HandleTypeDef hi2c4;

LTDC_HandleTypeDef hltdc;

QSPI_HandleTypeDef hqspi;

RTC_HandleTypeDef hrtc;

SAI_HandleTypeDef hsai_BlockA1;
DMA_HandleTypeDef hdma_sai1_a;

TIM_HandleTypeDef htim1;
TIM_HandleTypeDef htim3;
TIM_HandleTypeDef htim12;

UART_HandleTypeDef huart1;
DMA_HandleTypeDef hdma_usart1_rx;
DMA_HandleTypeDef hdma_usart1_tx;

SDRAM_HandleTypeDef hsdram1;

/* Definitions for defaultTask */
osThreadId_t defaultTaskHandle;
const osThreadAttr_t defaultTask_attributes = {
  .name = "defaultTask",
  .stack_size = 128 * 4,
  .priority = (osPriority_t) osPriorityNormal,
};
/* Definitions for audio_producer */
osThreadId_t audio_producerHandle;
const osThreadAttr_t audio_producer_attributes = {
  .name = "audio_producer",
  .stack_size = 1280 * 4,
  .priority = (osPriority_t) osPriorityNormal7,
};
/* Definitions for uart_handler */
osThreadId_t uart_handlerHandle;
const osThreadAttr_t uart_handler_attributes = {
  .name = "uart_handler",
  .stack_size = 128 * 4,
  .priority = (osPriority_t) osPriorityLow,
};
/* Definitions for audio_filter */
osThreadId_t audio_filterHandle;
const osThreadAttr_t audio_filter_attributes = {
  .name = "audio_filter",
  .stack_size = 1280 * 4,
  .priority = (osPriority_t) osPriorityNormal7,
};
/* Definitions for display_control */
osThreadId_t display_controlHandle;
const osThreadAttr_t display_control_attributes = {
  .name = "display_control",
  .stack_size = 2048 * 4,
  .priority = (osPriority_t) osPriorityBelowNormal7,
};
/* USER CODE BEGIN PV */

/* Minimum unused display-task stack since startup, in bytes (inspect in GDB). */
volatile uint32_t g_display_stack_min_free_bytes;

static FT6X06_TS_Drv_t ft6x06_ts_driver;
static FT6X06_Object_t ft6x06_object;

/* USER CODE END PV */

void SystemClock_Config(void);
void PeriphCommonClock_Config(void);
static void MPU_Config(void);
static void MX_GPIO_Init(void);
static void MX_DMA_Init(void);
static void MX_FMC_Init(void);
static void MX_LTDC_Init(void);
static void MX_QUADSPI_Init(void);
static void MX_RTC_Init(void);
static void MX_SAI1_Init(void);
static void MX_TIM1_Init(void);
static void MX_TIM3_Init(void);
static void MX_TIM12_Init(void);
static void MX_DFSDM1_Init(void);
static void MX_CRC_Init(void);
static void MX_USART1_UART_Init(void);
static void MX_I2C4_Init(void);
static void MX_DMA2D_Init(void);
static void MX_DSIHOST_DSI_Init(void);
void StartDefaultTask(void *argument);
void start_audio_producer(void *argument);
void start_uart_handler(void *argument);
void start_audio_filter(void *argument);
void start_display_control(void *argument);

/* USER CODE BEGIN PFP */

#define TS_I2C_ADDRESS                   ((uint16_t)0x54)
#define TS_I2C_ADDRESS_A02               ((uint16_t)0x70)

static int32_t ft6x06_ts_init(void) {

  const int res = HAL_I2C_IsDeviceReady(&hi2c4, TS_I2C_ADDRESS, 3, HAL_MAX_DELAY);
  if (res != HAL_OK) {
    return FT6X06_ERROR;
  }

  return FT6X06_OK;
}

static int32_t ft6x06_ts_deinit(void) {
  return FT6X06_OK;
}

static int32_t ft6x06_ts_read_id(void) {
  return FT6X06_OK;
}

static int32_t ft6x06_ts_read_register(uint16_t dev_addr, uint16_t reg,
    uint8_t * data, uint16_t length) {

  const int res = HAL_I2C_Mem_Read(&hi2c4, dev_addr, reg,
    I2C_MEMADD_SIZE_8BIT, (uint8_t *)data, length, HAL_MAX_DELAY);

  if (res != HAL_OK) {
    return FT6X06_ERROR;
  }

  return FT6X06_OK;
}

static int32_t ft6x06_ts_write_register(uint16_t dev_addr, uint16_t reg,
    uint8_t * data, uint16_t length) {

  const int res = HAL_I2C_Mem_Write(&hi2c4, dev_addr, reg,
    I2C_MEMADD_SIZE_8BIT, (uint8_t *)data, length, HAL_MAX_DELAY);

  if (res != HAL_OK) {
    return FT6X06_ERROR;
  }

  return FT6X06_OK;
}

static int32_t ft6x06_ts_get_tick(void) {
  return HAL_GetTick();
}

/* USER CODE END PFP */

int main(void)
{

  /* MPU Configuration--------------------------------------------------------*/
  MPU_Config();

  /* MCU Configuration--------------------------------------------------------*/

  /* Reset of all peripherals, Initializes the Flash interface and the Systick. */
  HAL_Init();

  /* Configure the system clock */
  SystemClock_Config();

  /* Configure the peripherals common clocks */
  PeriphCommonClock_Config();

  /* Initialize all configured peripherals */
  MX_GPIO_Init();
  MX_DMA_Init();
  MX_FMC_Init();
  MX_LTDC_Init();
  MX_QUADSPI_Init();
  MX_RTC_Init();
  MX_SAI1_Init();
  MX_TIM1_Init();
  MX_TIM3_Init();
  MX_TIM12_Init();
  MX_DFSDM1_Init();
  MX_CRC_Init();
  MX_USART1_UART_Init();
  MX_I2C4_Init();
  MX_DMA2D_Init();
  MX_DSIHOST_DSI_Init();
  /* USER CODE BEGIN 2 */

  HAL_GPIO_WritePin(
		LD_USER1_GPIO_Port,
		LD_USER1_Pin,
		GPIO_PIN_SET);

  HAL_GPIO_WritePin(
  		LD_USER2_GPIO_Port,
  		LD_USER2_Pin,
  		GPIO_PIN_SET);

  HAL_Delay(10);

  FT6X06_IO_t ft6x06_io = {
    .Init = ft6x06_ts_init,
    .DeInit = ft6x06_ts_deinit,
    .Address = TS_I2C_ADDRESS,
    .WriteReg = ft6x06_ts_write_register,
    .ReadReg = ft6x06_ts_read_register,
    .GetTick = ft6x06_ts_get_tick
  };

  FT6X06_RegisterBusIO(&ft6x06_object, &ft6x06_io);

  FT6X06_Init(&ft6x06_object);

  FT6X06_State_t ts_state;
  FT6X06_GetState(&ft6x06_object, &ts_state);

  /* USER CODE END 2 */

  /* Init scheduler */
  osKernelInitialize();

  /* Create the thread(s) */
  /* creation of defaultTask */
  defaultTaskHandle = osThreadNew(StartDefaultTask, NULL, &defaultTask_attributes);

  /* creation of audio_producer */
  audio_producerHandle = osThreadNew(start_audio_producer, NULL, &audio_producer_attributes);

  /* creation of uart_handler */
  uart_handlerHandle = osThreadNew(start_uart_handler, NULL, &uart_handler_attributes);

  /* creation of audio_filter */
  audio_filterHandle = osThreadNew(start_audio_filter, NULL, &audio_filter_attributes);

  /* creation of display_control */
  display_controlHandle = osThreadNew(start_display_control, NULL, &display_control_attributes);

  /* Start scheduler */
  osKernelStart();

  /* We should never get here as control is now taken by the scheduler */

  /* Infinite loop */
  while (1)
  {

  }
}

void SystemClock_Config(void)
{
  RCC_OscInitTypeDef RCC_OscInitStruct = {0};
  RCC_ClkInitTypeDef RCC_ClkInitStruct = {0};

  /** Configure LSE Drive Capability
  */
  HAL_PWR_EnableBkUpAccess();

  /** Configure the main internal regulator output voltage
  */
  __HAL_RCC_PWR_CLK_ENABLE();
  __HAL_PWR_VOLTAGESCALING_CONFIG(PWR_REGULATOR_VOLTAGE_SCALE1);

  /** Initializes the RCC Oscillators according to the specified parameters
  * in the RCC_OscInitTypeDef structure.
  */
  RCC_OscInitStruct.OscillatorType = RCC_OSCILLATORTYPE_HSI|RCC_OSCILLATORTYPE_LSI
                              |RCC_OSCILLATORTYPE_HSE;
  RCC_OscInitStruct.HSEState = RCC_HSE_ON;
  RCC_OscInitStruct.HSIState = RCC_HSI_ON;
  RCC_OscInitStruct.HSICalibrationValue = RCC_HSICALIBRATION_DEFAULT;
  RCC_OscInitStruct.LSIState = RCC_LSI_ON;
  RCC_OscInitStruct.PLL.PLLState = RCC_PLL_ON;
  RCC_OscInitStruct.PLL.PLLSource = RCC_PLLSOURCE_HSI;
  RCC_OscInitStruct.PLL.PLLM = 8;
  RCC_OscInitStruct.PLL.PLLN = 180;
  RCC_OscInitStruct.PLL.PLLP = RCC_PLLP_DIV2;
  RCC_OscInitStruct.PLL.PLLQ = 4;
  RCC_OscInitStruct.PLL.PLLR = 2;
  if (HAL_RCC_OscConfig(&RCC_OscInitStruct) != HAL_OK)
  {
    Error_Handler();
  }

  /** Initializes the CPU, AHB and APB buses clocks
  */
  RCC_ClkInitStruct.ClockType = RCC_CLOCKTYPE_HCLK|RCC_CLOCKTYPE_SYSCLK
                              |RCC_CLOCKTYPE_PCLK1|RCC_CLOCKTYPE_PCLK2;
  RCC_ClkInitStruct.SYSCLKSource = RCC_SYSCLKSOURCE_PLLCLK;
  RCC_ClkInitStruct.AHBCLKDivider = RCC_SYSCLK_DIV1;
  RCC_ClkInitStruct.APB1CLKDivider = RCC_HCLK_DIV4;
  RCC_ClkInitStruct.APB2CLKDivider = RCC_HCLK_DIV2;

  if (HAL_RCC_ClockConfig(&RCC_ClkInitStruct, FLASH_LATENCY_5) != HAL_OK)
  {
    Error_Handler();
  }
  HAL_RCC_MCOConfig(RCC_MCO1, RCC_MCO1SOURCE_HSI, RCC_MCODIV_1);
}

void PeriphCommonClock_Config(void)
{
  RCC_PeriphCLKInitTypeDef PeriphClkInitStruct = {0};

  /** Initializes the peripherals clock
  */
  PeriphClkInitStruct.PeriphClockSelection = RCC_PERIPHCLK_LTDC|RCC_PERIPHCLK_SAI1;
  PeriphClkInitStruct.PLLSAI.PLLSAIN = 96;
  PeriphClkInitStruct.PLLSAI.PLLSAIR = 3;
  PeriphClkInitStruct.PLLSAI.PLLSAIQ = 3;
  PeriphClkInitStruct.PLLSAI.PLLSAIP = RCC_PLLSAIP_DIV4;
  PeriphClkInitStruct.PLLSAIDivQ = 1;
  PeriphClkInitStruct.PLLSAIDivR = RCC_PLLSAIDIVR_2;
  PeriphClkInitStruct.Sai1ClockSelection = RCC_SAI1CLKSOURCE_PLLSAI;
  if (HAL_RCCEx_PeriphCLKConfig(&PeriphClkInitStruct) != HAL_OK)
  {
    Error_Handler();
  }
}

static void MX_CRC_Init(void)
{

  hcrc.Instance = CRC;
  hcrc.Init.DefaultPolynomialUse = DEFAULT_POLYNOMIAL_ENABLE;
  hcrc.Init.DefaultInitValueUse = DEFAULT_INIT_VALUE_ENABLE;
  hcrc.Init.InputDataInversionMode = CRC_INPUTDATA_INVERSION_NONE;
  hcrc.Init.OutputDataInversionMode = CRC_OUTPUTDATA_INVERSION_DISABLE;
  hcrc.InputDataFormat = CRC_INPUTDATA_FORMAT_BYTES;
  if (HAL_CRC_Init(&hcrc) != HAL_OK)
  {
    Error_Handler();
  }

}

static void MX_DFSDM1_Init(void)
{

  /* USER CODE BEGIN DFSDM1_Init 1 */
  /**__HAL_DFSDM_FILTER_RESET_HANDLE_STATE(hdfsdm1_filter0);
  __HAL_DFSDM_CHANNEL_RESET_HANDLE_STATE(hdfsdm1_channel0);/

  /* USER CODE END DFSDM1_Init 1 */
  hdfsdm1_filter0.Instance = DFSDM1_Filter0;
  hdfsdm1_filter0.Init.RegularParam.Trigger = DFSDM_FILTER_SW_TRIGGER;
  hdfsdm1_filter0.Init.RegularParam.FastMode = ENABLE;
  hdfsdm1_filter0.Init.RegularParam.DmaMode = ENABLE;
  hdfsdm1_filter0.Init.InjectedParam.Trigger = DFSDM_FILTER_SW_TRIGGER;
  hdfsdm1_filter0.Init.InjectedParam.ScanMode = ENABLE;
  hdfsdm1_filter0.Init.InjectedParam.DmaMode = ENABLE;
  hdfsdm1_filter0.Init.InjectedParam.ExtTrigger = DFSDM_FILTER_EXT_TRIG_TIM1_TRGO;
  hdfsdm1_filter0.Init.InjectedParam.ExtTriggerEdge = DFSDM_FILTER_EXT_TRIG_RISING_EDGE;
  hdfsdm1_filter0.Init.FilterParam.SincOrder = DFSDM_FILTER_SINC3_ORDER;
  hdfsdm1_filter0.Init.FilterParam.Oversampling = 50;
  hdfsdm1_filter0.Init.FilterParam.IntOversampling = 1;
  HAL_DFSDM_FilterInit(&hdfsdm1_filter0);
  hdfsdm1_channel0.Instance = DFSDM1_Channel0;
  hdfsdm1_channel0.Init.OutputClock.Activation = ENABLE;
  hdfsdm1_channel0.Init.OutputClock.Selection = DFSDM_CHANNEL_OUTPUT_CLOCK_SYSTEM;
  hdfsdm1_channel0.Init.OutputClock.Divider = 75;
  hdfsdm1_channel0.Init.Input.Multiplexer = DFSDM_CHANNEL_EXTERNAL_INPUTS;
  hdfsdm1_channel0.Init.Input.DataPacking = DFSDM_CHANNEL_STANDARD_MODE;
  hdfsdm1_channel0.Init.Input.Pins = DFSDM_CHANNEL_FOLLOWING_CHANNEL_PINS;
  hdfsdm1_channel0.Init.SerialInterface.Type = DFSDM_CHANNEL_SPI_FALLING;
  hdfsdm1_channel0.Init.SerialInterface.SpiClock = DFSDM_CHANNEL_SPI_CLOCK_INTERNAL;
  hdfsdm1_channel0.Init.Awd.FilterOrder = DFSDM_CHANNEL_FASTSINC_ORDER;
  hdfsdm1_channel0.Init.Awd.Oversampling = 1;
  hdfsdm1_channel0.Init.Offset = 0;
  hdfsdm1_channel0.Init.RightBitShift = 0;
  if (HAL_DFSDM_ChannelInit(&hdfsdm1_channel0) != HAL_OK)
  {
    Error_Handler();
  }
  HAL_DFSDM_FilterConfigRegChannel(&hdfsdm1_filter0, DFSDM_CHANNEL_0, DFSDM_CONTINUOUS_CONV_ON);
  HAL_DFSDM_FilterConfigInjChannel(&hdfsdm1_filter0, DFSDM_CHANNEL_0);

}

static void MX_DMA2D_Init(void)
{

  hdma2d.Instance = DMA2D;
  hdma2d.Init.Mode = DMA2D_M2M;
  hdma2d.Init.ColorMode = DMA2D_OUTPUT_ARGB8888;
  hdma2d.Init.OutputOffset = 0;
  hdma2d.LayerCfg[1].InputOffset = 0;
  hdma2d.LayerCfg[1].InputColorMode = DMA2D_INPUT_ARGB8888;
  hdma2d.LayerCfg[1].AlphaMode = DMA2D_NO_MODIF_ALPHA;
  hdma2d.LayerCfg[1].InputAlpha = 0;
  hdma2d.LayerCfg[1].AlphaInverted = DMA2D_REGULAR_ALPHA;
  hdma2d.LayerCfg[1].RedBlueSwap = DMA2D_RB_REGULAR;
  if (HAL_DMA2D_Init(&hdma2d) != HAL_OK)
  {
    Error_Handler();
  }
  if (HAL_DMA2D_ConfigLayer(&hdma2d, 1) != HAL_OK)
  {
    Error_Handler();
  }

}

static void MX_DSIHOST_DSI_Init(void)
{

  DSI_PLLInitTypeDef PLLInit = {0};
  DSI_HOST_TimeoutTypeDef HostTimeouts = {0};
  DSI_PHY_TimerTypeDef PhyTimings = {0};
  DSI_LPCmdTypeDef LPCmd = {0};
  DSI_CmdCfgTypeDef CmdCfg = {0};

  hdsi.Instance = DSI;
  hdsi.Init.AutomaticClockLaneControl = DSI_AUTO_CLK_LANE_CTRL_DISABLE;
  hdsi.Init.TXEscapeCkdiv = 4;
  hdsi.Init.NumberOfLanes = DSI_TWO_DATA_LANES;
  PLLInit.PLLNDIV = 20;
  PLLInit.PLLIDF = DSI_PLL_IN_DIV1;
  PLLInit.PLLODF = DSI_PLL_OUT_DIV1;
  if (HAL_DSI_Init(&hdsi, &PLLInit) != HAL_OK)
  {
    Error_Handler();
  }
  HostTimeouts.TimeoutCkdiv = 1;
  HostTimeouts.HighSpeedTransmissionTimeout = 0;
  HostTimeouts.LowPowerReceptionTimeout = 0;
  HostTimeouts.HighSpeedReadTimeout = 0;
  HostTimeouts.LowPowerReadTimeout = 0;
  HostTimeouts.HighSpeedWriteTimeout = 0;
  HostTimeouts.HighSpeedWritePrespMode = DSI_HS_PM_DISABLE;
  HostTimeouts.LowPowerWriteTimeout = 0;
  HostTimeouts.BTATimeout = 0;
  if (HAL_DSI_ConfigHostTimeouts(&hdsi, &HostTimeouts) != HAL_OK)
  {
    Error_Handler();
  }
  PhyTimings.ClockLaneHS2LPTime = 28;
  PhyTimings.ClockLaneLP2HSTime = 33;
  PhyTimings.DataLaneHS2LPTime = 15;
  PhyTimings.DataLaneLP2HSTime = 25;
  PhyTimings.DataLaneMaxReadTime = 0;
  PhyTimings.StopWaitTime = 10;
  if (HAL_DSI_ConfigPhyTimer(&hdsi, &PhyTimings) != HAL_OK)
  {
    Error_Handler();
  }
  if (HAL_DSI_ConfigFlowControl(&hdsi, DSI_FLOW_CONTROL_BTA) != HAL_OK)
  {
    Error_Handler();
  }
  if (HAL_DSI_SetLowPowerRXFilter(&hdsi, 10000) != HAL_OK)
  {
    Error_Handler();
  }
  if (HAL_DSI_ConfigErrorMonitor(&hdsi, HAL_DSI_ERROR_NONE) != HAL_OK)
  {
    Error_Handler();
  }
  LPCmd.LPGenShortWriteNoP = DSI_LP_GSW0P_DISABLE;
  LPCmd.LPGenShortWriteOneP = DSI_LP_GSW1P_DISABLE;
  LPCmd.LPGenShortWriteTwoP = DSI_LP_GSW2P_DISABLE;
  LPCmd.LPGenShortReadNoP = DSI_LP_GSR0P_DISABLE;
  LPCmd.LPGenShortReadOneP = DSI_LP_GSR1P_DISABLE;
  LPCmd.LPGenShortReadTwoP = DSI_LP_GSR2P_DISABLE;
  LPCmd.LPGenLongWrite = DSI_LP_GLW_DISABLE;
  LPCmd.LPDcsShortWriteNoP = DSI_LP_DSW0P_DISABLE;
  LPCmd.LPDcsShortWriteOneP = DSI_LP_DSW1P_DISABLE;
  LPCmd.LPDcsShortReadNoP = DSI_LP_DSR0P_DISABLE;
  LPCmd.LPDcsLongWrite = DSI_LP_DLW_DISABLE;
  LPCmd.LPMaxReadPacket = DSI_LP_MRDP_DISABLE;
  LPCmd.AcknowledgeRequest = DSI_ACKNOWLEDGE_DISABLE;
  if (HAL_DSI_ConfigCommand(&hdsi, &LPCmd) != HAL_OK)
  {
    Error_Handler();
  }
  CmdCfg.VirtualChannelID = 0;
  CmdCfg.ColorCoding = DSI_RGB888;
  CmdCfg.CommandSize = 800;
  CmdCfg.TearingEffectSource = DSI_TE_DSILINK;
  CmdCfg.TearingEffectPolarity = DSI_TE_RISING_EDGE;
  CmdCfg.HSPolarity = DSI_HSYNC_ACTIVE_LOW;
  CmdCfg.VSPolarity = DSI_VSYNC_ACTIVE_LOW;
  CmdCfg.DEPolarity = DSI_DATA_ENABLE_ACTIVE_HIGH;
  CmdCfg.VSyncPol = DSI_VSYNC_FALLING;
  CmdCfg.AutomaticRefresh = DSI_AR_ENABLE;
  CmdCfg.TEAcknowledgeRequest = DSI_TE_ACKNOWLEDGE_DISABLE;
  if (HAL_DSI_ConfigAdaptedCommandMode(&hdsi, &CmdCfg) != HAL_OK)
  {
    Error_Handler();
  }
  if (HAL_DSI_SetGenericVCID(&hdsi, 0) != HAL_OK)
  {
    Error_Handler();
  }

}

static void MX_I2C4_Init(void)
{

  hi2c4.Instance = I2C4;
  hi2c4.Init.Timing = 0xC0000E12;
  hi2c4.Init.OwnAddress1 = 0;
  hi2c4.Init.AddressingMode = I2C_ADDRESSINGMODE_7BIT;
  hi2c4.Init.DualAddressMode = I2C_DUALADDRESS_DISABLE;
  hi2c4.Init.OwnAddress2 = 0;
  hi2c4.Init.OwnAddress2Masks = I2C_OA2_NOMASK;
  hi2c4.Init.GeneralCallMode = I2C_GENERALCALL_DISABLE;
  hi2c4.Init.NoStretchMode = I2C_NOSTRETCH_DISABLE;
  if (HAL_I2C_Init(&hi2c4) != HAL_OK)
  {
    Error_Handler();
  }

  /** Configure Analogue filter
  */
  if (HAL_I2CEx_ConfigAnalogFilter(&hi2c4, I2C_ANALOGFILTER_ENABLE) != HAL_OK)
  {
    Error_Handler();
  }

  /** Configure Digital filter
  */
  if (HAL_I2CEx_ConfigDigitalFilter(&hi2c4, 0) != HAL_OK)
  {
    Error_Handler();
  }

}

static void MX_LTDC_Init(void)
{

  LTDC_LayerCfgTypeDef pLayerCfg = {0};

  hltdc.Instance = LTDC;
  hltdc.Init.HSPolarity = LTDC_HSPOLARITY_AL;
  hltdc.Init.VSPolarity = LTDC_VSPOLARITY_AL;
  hltdc.Init.DEPolarity = LTDC_DEPOLARITY_AL;
  hltdc.Init.PCPolarity = LTDC_PCPOLARITY_IPC;
  hltdc.Init.HorizontalSync = 0;
  hltdc.Init.VerticalSync = 0;
  hltdc.Init.AccumulatedHBP = 1;
  hltdc.Init.AccumulatedVBP = 1;
  hltdc.Init.AccumulatedActiveW = 801;
  hltdc.Init.AccumulatedActiveH = 481;
  hltdc.Init.TotalWidth = 802;
  hltdc.Init.TotalHeigh = 482;
  hltdc.Init.Backcolor.Blue = 0;
  hltdc.Init.Backcolor.Green = 0;
  hltdc.Init.Backcolor.Red = 0;
  if (HAL_LTDC_Init(&hltdc) != HAL_OK)
  {
    Error_Handler();
  }
  pLayerCfg.WindowX0 = 0;
  pLayerCfg.WindowX1 = 800;
  pLayerCfg.WindowY0 = 0;
  pLayerCfg.WindowY1 = 480;
  pLayerCfg.PixelFormat = LTDC_PIXEL_FORMAT_ARGB8888;
  pLayerCfg.Alpha = 255;
  pLayerCfg.Alpha0 = 0;
  pLayerCfg.BlendingFactor1 = LTDC_BLENDING_FACTOR1_PAxCA;
  pLayerCfg.BlendingFactor2 = LTDC_BLENDING_FACTOR2_PAxCA;
  pLayerCfg.FBStartAdress = 0xC0000000;
  pLayerCfg.ImageWidth = 800;
  pLayerCfg.ImageHeight = 480;
  pLayerCfg.Backcolor.Blue = 0;
  pLayerCfg.Backcolor.Green = 0;
  pLayerCfg.Backcolor.Red = 0;
  if (HAL_LTDC_ConfigLayer(&hltdc, &pLayerCfg, 0) != HAL_OK)
  {
    Error_Handler();
  }

}

static void MX_QUADSPI_Init(void)
{

  /* QUADSPI parameter configuration*/
  hqspi.Instance = QUADSPI;
  hqspi.Init.ClockPrescaler = 1;
  hqspi.Init.FifoThreshold = 16;
  hqspi.Init.SampleShifting = QSPI_SAMPLE_SHIFTING_HALFCYCLE;
  hqspi.Init.FlashSize = 26;
  hqspi.Init.ChipSelectHighTime = QSPI_CS_HIGH_TIME_4_CYCLE;
  hqspi.Init.ClockMode = QSPI_CLOCK_MODE_0;
  hqspi.Init.FlashID = QSPI_FLASH_ID_1;
  hqspi.Init.DualFlash = QSPI_DUALFLASH_DISABLE;
  if (HAL_QSPI_Init(&hqspi) != HAL_OK)
  {
    Error_Handler();
  }

}

static void MX_RTC_Init(void)
{

  RTC_TimeTypeDef sTime = {0};
  RTC_DateTypeDef sDate = {0};
  RTC_AlarmTypeDef sAlarm = {0};

  /** Initialize RTC Only
  */
  hrtc.Instance = RTC;
  hrtc.Init.HourFormat = RTC_HOURFORMAT_24;
  hrtc.Init.AsynchPrediv = 127;
  hrtc.Init.SynchPrediv = 255;
  hrtc.Init.OutPut = RTC_OUTPUT_ALARMA;
  hrtc.Init.OutPutPolarity = RTC_OUTPUT_POLARITY_HIGH;
  hrtc.Init.OutPutType = RTC_OUTPUT_TYPE_OPENDRAIN;
  if (HAL_RTC_Init(&hrtc) != HAL_OK)
  {
    Error_Handler();
  }

  /** Initialize RTC and set the Time and Date
  */
  sTime.Hours = 0x0;
  sTime.Minutes = 0x0;
  sTime.Seconds = 0x0;
  sTime.DayLightSaving = RTC_DAYLIGHTSAVING_NONE;
  sTime.StoreOperation = RTC_STOREOPERATION_RESET;
  if (HAL_RTC_SetTime(&hrtc, &sTime, RTC_FORMAT_BCD) != HAL_OK)
  {
    Error_Handler();
  }
  sDate.WeekDay = RTC_WEEKDAY_MONDAY;
  sDate.Month = RTC_MONTH_JANUARY;
  sDate.Date = 0x1;
  sDate.Year = 0x0;
  if (HAL_RTC_SetDate(&hrtc, &sDate, RTC_FORMAT_BCD) != HAL_OK)
  {
    Error_Handler();
  }

  /** Enable the Alarm A
  */
  sAlarm.AlarmTime.Hours = 0x0;
  sAlarm.AlarmTime.Minutes = 0x0;
  sAlarm.AlarmTime.Seconds = 0x0;
  sAlarm.AlarmTime.SubSeconds = 0x0;
  sAlarm.AlarmTime.DayLightSaving = RTC_DAYLIGHTSAVING_NONE;
  sAlarm.AlarmTime.StoreOperation = RTC_STOREOPERATION_RESET;
  sAlarm.AlarmMask = RTC_ALARMMASK_NONE;
  sAlarm.AlarmSubSecondMask = RTC_ALARMSUBSECONDMASK_ALL;
  sAlarm.AlarmDateWeekDaySel = RTC_ALARMDATEWEEKDAYSEL_DATE;
  sAlarm.AlarmDateWeekDay = 0x1;
  sAlarm.Alarm = RTC_ALARM_A;
  if (HAL_RTC_SetAlarm(&hrtc, &sAlarm, RTC_FORMAT_BCD) != HAL_OK)
  {
    Error_Handler();
  }

  /** Enable the Alarm B
  */
  sAlarm.Alarm = RTC_ALARM_B;
  if (HAL_RTC_SetAlarm(&hrtc, &sAlarm, RTC_FORMAT_BCD) != HAL_OK)
  {
    Error_Handler();
  }

}

static void MX_SAI1_Init(void)
{

  hsai_BlockA1.Instance = SAI1_Block_A;
  hsai_BlockA1.Init.Protocol = SAI_FREE_PROTOCOL;
  hsai_BlockA1.Init.AudioMode = SAI_MODEMASTER_TX;
  hsai_BlockA1.Init.DataSize = SAI_DATASIZE_16;
  hsai_BlockA1.Init.FirstBit = SAI_FIRSTBIT_MSB;
  hsai_BlockA1.Init.ClockStrobing = SAI_CLOCKSTROBING_FALLINGEDGE;
  hsai_BlockA1.Init.Synchro = SAI_ASYNCHRONOUS;
  hsai_BlockA1.Init.OutputDrive = SAI_OUTPUTDRIVE_DISABLE;
  hsai_BlockA1.Init.NoDivider = SAI_MASTERDIVIDER_ENABLE;
  hsai_BlockA1.Init.FIFOThreshold = SAI_FIFOTHRESHOLD_EMPTY;
  hsai_BlockA1.Init.AudioFrequency = SAI_AUDIO_FREQUENCY_44K;
  hsai_BlockA1.Init.SynchroExt = SAI_SYNCEXT_DISABLE;
  hsai_BlockA1.Init.MonoStereoMode = SAI_STEREOMODE;
  hsai_BlockA1.Init.CompandingMode = SAI_NOCOMPANDING;
  hsai_BlockA1.Init.TriState = SAI_OUTPUT_NOTRELEASED;
  hsai_BlockA1.FrameInit.FrameLength = 32;
  hsai_BlockA1.FrameInit.ActiveFrameLength = 16;
  hsai_BlockA1.FrameInit.FSDefinition = SAI_FS_CHANNEL_IDENTIFICATION;
  hsai_BlockA1.FrameInit.FSPolarity = SAI_FS_ACTIVE_LOW;
  hsai_BlockA1.FrameInit.FSOffset = SAI_FS_FIRSTBIT;
  hsai_BlockA1.SlotInit.FirstBitOffset = 0;
  hsai_BlockA1.SlotInit.SlotSize = SAI_SLOTSIZE_DATASIZE;
  hsai_BlockA1.SlotInit.SlotNumber = 2;
  hsai_BlockA1.SlotInit.SlotActive = 0x00000003;
  if (HAL_SAI_Init(&hsai_BlockA1) != HAL_OK)
  {
    Error_Handler();
  }

}

static void MX_TIM1_Init(void)
{

  TIM_ClockConfigTypeDef sClockSourceConfig = {0};
  TIM_MasterConfigTypeDef sMasterConfig = {0};

  htim1.Instance = TIM1;
  htim1.Init.Prescaler = 0;
  htim1.Init.CounterMode = TIM_COUNTERMODE_UP;
  htim1.Init.Period = 65535;
  htim1.Init.ClockDivision = TIM_CLOCKDIVISION_DIV1;
  htim1.Init.RepetitionCounter = 0;
  htim1.Init.AutoReloadPreload = TIM_AUTORELOAD_PRELOAD_DISABLE;
  if (HAL_TIM_Base_Init(&htim1) != HAL_OK)
  {
    Error_Handler();
  }
  sClockSourceConfig.ClockSource = TIM_CLOCKSOURCE_INTERNAL;
  if (HAL_TIM_ConfigClockSource(&htim1, &sClockSourceConfig) != HAL_OK)
  {
    Error_Handler();
  }
  sMasterConfig.MasterOutputTrigger = TIM_TRGO_RESET;
  sMasterConfig.MasterOutputTrigger2 = TIM_TRGO2_RESET;
  sMasterConfig.MasterSlaveMode = TIM_MASTERSLAVEMODE_DISABLE;
  if (HAL_TIMEx_MasterConfigSynchronization(&htim1, &sMasterConfig) != HAL_OK)
  {
    Error_Handler();
  }

}

static void MX_TIM3_Init(void)
{

  TIM_MasterConfigTypeDef sMasterConfig = {0};
  TIM_OC_InitTypeDef sConfigOC = {0};

  htim3.Instance = TIM3;
  htim3.Init.Prescaler = 0;
  htim3.Init.CounterMode = TIM_COUNTERMODE_UP;
  htim3.Init.Period = 65535;
  htim3.Init.ClockDivision = TIM_CLOCKDIVISION_DIV1;
  htim3.Init.AutoReloadPreload = TIM_AUTORELOAD_PRELOAD_DISABLE;
  if (HAL_TIM_PWM_Init(&htim3) != HAL_OK)
  {
    Error_Handler();
  }
  sMasterConfig.MasterOutputTrigger = TIM_TRGO_RESET;
  sMasterConfig.MasterSlaveMode = TIM_MASTERSLAVEMODE_DISABLE;
  if (HAL_TIMEx_MasterConfigSynchronization(&htim3, &sMasterConfig) != HAL_OK)
  {
    Error_Handler();
  }
  sConfigOC.OCMode = TIM_OCMODE_PWM1;
  sConfigOC.Pulse = 0;
  sConfigOC.OCPolarity = TIM_OCPOLARITY_HIGH;
  sConfigOC.OCFastMode = TIM_OCFAST_DISABLE;
  if (HAL_TIM_PWM_ConfigChannel(&htim3, &sConfigOC, TIM_CHANNEL_3) != HAL_OK)
  {
    Error_Handler();
  }
  HAL_TIM_MspPostInit(&htim3);

}

static void MX_TIM12_Init(void)
{

  TIM_OC_InitTypeDef sConfigOC = {0};

  htim12.Instance = TIM12;
  htim12.Init.Prescaler = 0;
  htim12.Init.CounterMode = TIM_COUNTERMODE_UP;
  htim12.Init.Period = 65535;
  htim12.Init.ClockDivision = TIM_CLOCKDIVISION_DIV1;
  htim12.Init.AutoReloadPreload = TIM_AUTORELOAD_PRELOAD_DISABLE;
  if (HAL_TIM_PWM_Init(&htim12) != HAL_OK)
  {
    Error_Handler();
  }
  sConfigOC.OCMode = TIM_OCMODE_PWM1;
  sConfigOC.Pulse = 0;
  sConfigOC.OCPolarity = TIM_OCPOLARITY_HIGH;
  sConfigOC.OCFastMode = TIM_OCFAST_DISABLE;
  if (HAL_TIM_PWM_ConfigChannel(&htim12, &sConfigOC, TIM_CHANNEL_1) != HAL_OK)
  {
    Error_Handler();
  }
  HAL_TIM_MspPostInit(&htim12);

}

static void MX_USART1_UART_Init(void)
{

  huart1.Instance = USART1;
  huart1.Init.BaudRate = 1500000;
  huart1.Init.WordLength = UART_WORDLENGTH_8B;
  huart1.Init.StopBits = UART_STOPBITS_1;
  huart1.Init.Parity = UART_PARITY_NONE;
  huart1.Init.Mode = UART_MODE_TX_RX;
  huart1.Init.HwFlowCtl = UART_HWCONTROL_NONE;
  huart1.Init.OverSampling = UART_OVERSAMPLING_16;
  huart1.Init.OneBitSampling = UART_ONE_BIT_SAMPLE_DISABLE;
  huart1.AdvancedInit.AdvFeatureInit = UART_ADVFEATURE_NO_INIT;
  if (HAL_UART_Init(&huart1) != HAL_OK)
  {
    Error_Handler();
  }

}

static void MX_DMA_Init(void)
{

  /* DMA controller clock enable */
  __HAL_RCC_DMA2_CLK_ENABLE();

  /* DMA interrupt init */
  /* DMA2_Stream0_IRQn interrupt configuration */
  HAL_NVIC_SetPriority(DMA2_Stream0_IRQn, 5, 0);
  HAL_NVIC_EnableIRQ(DMA2_Stream0_IRQn);
  /* DMA2_Stream1_IRQn interrupt configuration */
  HAL_NVIC_SetPriority(DMA2_Stream1_IRQn, 5, 0);
  HAL_NVIC_EnableIRQ(DMA2_Stream1_IRQn);
  /* DMA2_Stream2_IRQn interrupt configuration */
  HAL_NVIC_SetPriority(DMA2_Stream2_IRQn, 5, 0);
  HAL_NVIC_EnableIRQ(DMA2_Stream2_IRQn);
  /* DMA2_Stream7_IRQn interrupt configuration */
  HAL_NVIC_SetPriority(DMA2_Stream7_IRQn, 5, 0);
  HAL_NVIC_EnableIRQ(DMA2_Stream7_IRQn);

}

/* FMC initialization function */
static void MX_FMC_Init(void)
{

  FMC_SDRAM_TimingTypeDef SdramTiming = {0};

  /** Perform the SDRAM1 memory initialization sequence
  */
  hsdram1.Instance = FMC_SDRAM_DEVICE;
  /* hsdram1.Init */
  hsdram1.Init.SDBank = FMC_SDRAM_BANK1;
  hsdram1.Init.ColumnBitsNumber = FMC_SDRAM_COLUMN_BITS_NUM_8;
  hsdram1.Init.RowBitsNumber = FMC_SDRAM_ROW_BITS_NUM_12;
  hsdram1.Init.MemoryDataWidth = FMC_SDRAM_MEM_BUS_WIDTH_32;
  hsdram1.Init.InternalBankNumber = FMC_SDRAM_INTERN_BANKS_NUM_4;
  hsdram1.Init.CASLatency = FMC_SDRAM_CAS_LATENCY_3;
  hsdram1.Init.WriteProtection = FMC_SDRAM_WRITE_PROTECTION_DISABLE;
  hsdram1.Init.SDClockPeriod = FMC_SDRAM_CLOCK_PERIOD_2;
  hsdram1.Init.ReadBurst = FMC_SDRAM_RBURST_ENABLE;
  hsdram1.Init.ReadPipeDelay = FMC_SDRAM_RPIPE_DELAY_0;
  /* SdramTiming */
  SdramTiming.LoadToActiveDelay = 2;
  SdramTiming.ExitSelfRefreshDelay = 7;
  SdramTiming.SelfRefreshTime = 4;
  SdramTiming.RowCycleDelay = 7;
  SdramTiming.WriteRecoveryTime = 2;
  SdramTiming.RPDelay = 2;
  SdramTiming.RCDDelay = 16;

  if (HAL_SDRAM_Init(&hsdram1, &SdramTiming) != HAL_OK)
  {
    Error_Handler( );
  }

  /* USER CODE BEGIN FMC_Init 2 */

  // config SDRAM: see example code:
  // https://github.com/STMicroelectronics/32f769idiscovery-bsp/blob/main/stm32f769i_discovery_sdram.c

  FMC_SDRAM_CommandTypeDef Command;

  // --------------------------------------------------------------------------
  // clock configuration enable command
  // --------------------------------------------------------------------------

  Command.CommandMode = FMC_SDRAM_CMD_CLK_ENABLE;
  Command.CommandTarget = FMC_SDRAM_CMD_TARGET_BANK1;
  Command.AutoRefreshNumber = 1;
  Command.ModeRegisterDefinition = 0;

  HAL_SDRAM_SendCommand(&hsdram1, &Command, 0xFFFF);

  HAL_Delay(1);

  // --------------------------------------------------------------------------
  // precharge all command:
  // --------------------------------------------------------------------------
  Command.CommandMode = FMC_SDRAM_CMD_PALL;
  Command.CommandTarget = FMC_SDRAM_CMD_TARGET_BANK1;
  Command.AutoRefreshNumber = 1;
  Command.ModeRegisterDefinition = 0;
  HAL_SDRAM_SendCommand(&hsdram1, &Command, 0xFFFF);

  HAL_Delay(1);

  // --------------------------------------------------------------------------
  // auto Refresh command
  // --------------------------------------------------------------------------
  Command.CommandMode            = FMC_SDRAM_CMD_AUTOREFRESH_MODE;
  Command.CommandTarget          = FMC_SDRAM_CMD_TARGET_BANK1;
  Command.AutoRefreshNumber      = 8;
  Command.ModeRegisterDefinition = 0;

  HAL_SDRAM_SendCommand(&hsdram1, &Command, 0xFFFF);

  HAL_Delay(1);

  // --------------------------------------------------------------------------
  // Program the external memory mode register
  // --------------------------------------------------------------------------

  const int SDRAM_MODEREG_BURST_LENGTH_1              = ((uint16_t)0x0000);
  const int SDRAM_MODEREG_BURST_LENGTH_2             = ((uint16_t)0x0001);
  const int SDRAM_MODEREG_BURST_LENGTH_4             = ((uint16_t)0x0002);
  const int SDRAM_MODEREG_BURST_LENGTH_8             = ((uint16_t)0x0004);
  const int SDRAM_MODEREG_BURST_TYPE_SEQUENTIAL      = ((uint16_t)0x0000);
  const int SDRAM_MODEREG_BURST_TYPE_INTERLEAVED     = ((uint16_t)0x0008);
  const int SDRAM_MODEREG_CAS_LATENCY_2              = ((uint16_t)0x0020);
  const int SDRAM_MODEREG_CAS_LATENCY_3              = ((uint16_t)0x0030);
  const int SDRAM_MODEREG_OPERATING_MODE_STANDARD    = ((uint16_t)0x0000);
  const int SDRAM_MODEREG_WRITEBURST_MODE_PROGRAMMED = ((uint16_t)0x0000);
  const int SDRAM_MODEREG_WRITEBURST_MODE_SINGLE     = ((uint16_t)0x0200);

  uint32_t tmpmrd = (uint32_t)SDRAM_MODEREG_BURST_LENGTH_1 |\
                     SDRAM_MODEREG_BURST_TYPE_SEQUENTIAL   |\
                     SDRAM_MODEREG_CAS_LATENCY_3           |\
                     SDRAM_MODEREG_OPERATING_MODE_STANDARD |\
                     SDRAM_MODEREG_WRITEBURST_MODE_SINGLE;

  Command.CommandMode            = FMC_SDRAM_CMD_LOAD_MODE;
  Command.CommandTarget          = FMC_SDRAM_CMD_TARGET_BANK1;
  Command.AutoRefreshNumber      = 1;
  Command.ModeRegisterDefinition = tmpmrd;

  HAL_SDRAM_SendCommand(&hsdram1, &Command, 0xFFFF);

  HAL_Delay(1);

  HAL_SDRAM_ProgramRefreshRate(&hsdram1, 0x056A);

  /* USER CODE END FMC_Init 2 */
}

static void MX_GPIO_Init(void)
{
  GPIO_InitTypeDef GPIO_InitStruct = {0};

  /* GPIO Ports Clock Enable */
  __HAL_RCC_GPIOE_CLK_ENABLE();
  __HAL_RCC_GPIOG_CLK_ENABLE();
  __HAL_RCC_GPIOB_CLK_ENABLE();
  __HAL_RCC_GPIOD_CLK_ENABLE();
  __HAL_RCC_GPIOC_CLK_ENABLE();
  __HAL_RCC_GPIOA_CLK_ENABLE();
  __HAL_RCC_GPIOJ_CLK_ENABLE();
  __HAL_RCC_GPIOI_CLK_ENABLE();
  __HAL_RCC_GPIOK_CLK_ENABLE();
  __HAL_RCC_GPIOF_CLK_ENABLE();
  __HAL_RCC_GPIOH_CLK_ENABLE();

  /*Configure GPIO pin Output Level */
  HAL_GPIO_WritePin(GPIOJ, LD_USER1_Pin|DSI_RESET_Pin|LD_USER2_Pin, GPIO_PIN_RESET);

  /*Configure GPIO pins : RMII_TXD1_Pin RMII_TXD0_Pin RMII_TX_EN_Pin */
  GPIO_InitStruct.Pin = RMII_TXD1_Pin|RMII_TXD0_Pin|RMII_TX_EN_Pin;
  GPIO_InitStruct.Mode = GPIO_MODE_AF_PP;
  GPIO_InitStruct.Pull = GPIO_NOPULL;
  GPIO_InitStruct.Speed = GPIO_SPEED_FREQ_VERY_HIGH;
  GPIO_InitStruct.Alternate = GPIO_AF11_ETH;
  HAL_GPIO_Init(GPIOG, &GPIO_InitStruct);

  /*Configure GPIO pins : ARDUINO_SCL_D15_Pin ARDUINO_SDA_D14_Pin */
  GPIO_InitStruct.Pin = ARDUINO_SCL_D15_Pin|ARDUINO_SDA_D14_Pin;
  GPIO_InitStruct.Mode = GPIO_MODE_AF_OD;
  GPIO_InitStruct.Pull = GPIO_PULLUP;
  GPIO_InitStruct.Speed = GPIO_SPEED_FREQ_LOW;
  GPIO_InitStruct.Alternate = GPIO_AF4_I2C1;
  HAL_GPIO_Init(GPIOB, &GPIO_InitStruct);

  /*Configure GPIO pins : ULPI_D7_Pin ULPI_D6_Pin ULPI_D5_Pin ULPI_D3_Pin
                           ULPI_D2_Pin ULPI_D1_Pin ULPI_D4_Pin */
  GPIO_InitStruct.Pin = ULPI_D7_Pin|ULPI_D6_Pin|ULPI_D5_Pin|ULPI_D3_Pin
                          |ULPI_D2_Pin|ULPI_D1_Pin|ULPI_D4_Pin;
  GPIO_InitStruct.Mode = GPIO_MODE_AF_PP;
  GPIO_InitStruct.Pull = GPIO_NOPULL;
  GPIO_InitStruct.Speed = GPIO_SPEED_FREQ_VERY_HIGH;
  GPIO_InitStruct.Alternate = GPIO_AF10_OTG_HS;
  HAL_GPIO_Init(GPIOB, &GPIO_InitStruct);

  /*Configure GPIO pins : uSD_D3_Pin uSD_D2_Pin */
  GPIO_InitStruct.Pin = uSD_D3_Pin|uSD_D2_Pin;
  GPIO_InitStruct.Mode = GPIO_MODE_AF_PP;
  GPIO_InitStruct.Pull = GPIO_NOPULL;
  GPIO_InitStruct.Speed = GPIO_SPEED_FREQ_VERY_HIGH;
  GPIO_InitStruct.Alternate = GPIO_AF10_SDMMC2;
  HAL_GPIO_Init(GPIOB, &GPIO_InitStruct);

  /*Configure GPIO pins : uSD_CMD_Pin uSD_CLK_Pin */
  GPIO_InitStruct.Pin = uSD_CMD_Pin|uSD_CLK_Pin;
  GPIO_InitStruct.Mode = GPIO_MODE_AF_PP;
  GPIO_InitStruct.Pull = GPIO_NOPULL;
  GPIO_InitStruct.Speed = GPIO_SPEED_FREQ_VERY_HIGH;
  GPIO_InitStruct.Alternate = GPIO_AF11_SDMMC2;
  HAL_GPIO_Init(GPIOD, &GPIO_InitStruct);

  /*Configure GPIO pin : WIFI_RX_Pin */
  GPIO_InitStruct.Pin = WIFI_RX_Pin;
  GPIO_InitStruct.Mode = GPIO_MODE_AF_PP;
  GPIO_InitStruct.Pull = GPIO_NOPULL;
  GPIO_InitStruct.Speed = GPIO_SPEED_FREQ_VERY_HIGH;
  GPIO_InitStruct.Alternate = GPIO_AF8_UART5;
  HAL_GPIO_Init(WIFI_RX_GPIO_Port, &GPIO_InitStruct);

  /*Configure GPIO pin : CEC_Pin */
  GPIO_InitStruct.Pin = CEC_Pin;
  GPIO_InitStruct.Mode = GPIO_MODE_AF_OD;
  GPIO_InitStruct.Pull = GPIO_NOPULL;
  GPIO_InitStruct.Speed = GPIO_SPEED_FREQ_LOW;
  GPIO_InitStruct.Alternate = GPIO_AF4_CEC;
  HAL_GPIO_Init(CEC_GPIO_Port, &GPIO_InitStruct);

  /*Configure GPIO pins : LD_USER1_Pin DSI_RESET_Pin LD_USER2_Pin */
  GPIO_InitStruct.Pin = LD_USER1_Pin|DSI_RESET_Pin|LD_USER2_Pin;
  GPIO_InitStruct.Mode = GPIO_MODE_OUTPUT_PP;
  GPIO_InitStruct.Pull = GPIO_NOPULL;
  GPIO_InitStruct.Speed = GPIO_SPEED_FREQ_LOW;
  HAL_GPIO_Init(GPIOJ, &GPIO_InitStruct);

  /*Configure GPIO pins : Audio_INT_Pin WIFI_RST_Pin ARD_D8_Pin ARD_D7_Pin
                           ARD_D4_Pin ARD_D2_Pin */
  GPIO_InitStruct.Pin = Audio_INT_Pin|WIFI_RST_Pin|ARD_D8_Pin|ARD_D7_Pin
                          |ARD_D4_Pin|ARD_D2_Pin;
  GPIO_InitStruct.Mode = GPIO_MODE_INPUT;
  GPIO_InitStruct.Pull = GPIO_NOPULL;
  HAL_GPIO_Init(GPIOJ, &GPIO_InitStruct);

  /*Configure GPIO pin : ARD_D13_SCK_Pin */
  GPIO_InitStruct.Pin = ARD_D13_SCK_Pin;
  GPIO_InitStruct.Mode = GPIO_MODE_AF_PP;
  GPIO_InitStruct.Pull = GPIO_NOPULL;
  GPIO_InitStruct.Speed = GPIO_SPEED_FREQ_LOW;
  GPIO_InitStruct.Alternate = GPIO_AF5_SPI2;
  HAL_GPIO_Init(ARD_D13_SCK_GPIO_Port, &GPIO_InitStruct);

  /*Configure GPIO pins : NC4_Pin NC5_Pin uSD_Detect_Pin LCD_BL_CTRL_Pin */
  GPIO_InitStruct.Pin = NC4_Pin|NC5_Pin|uSD_Detect_Pin|LCD_BL_CTRL_Pin;
  GPIO_InitStruct.Mode = GPIO_MODE_INPUT;
  GPIO_InitStruct.Pull = GPIO_NOPULL;
  HAL_GPIO_Init(GPIOI, &GPIO_InitStruct);

  /*Configure GPIO pins : NC3_Pin NC2_Pin NC1_Pin NC8_Pin
                           NC7_Pin */
  GPIO_InitStruct.Pin = NC3_Pin|NC2_Pin|NC1_Pin|NC8_Pin
                          |NC7_Pin;
  GPIO_InitStruct.Mode = GPIO_MODE_INPUT;
  GPIO_InitStruct.Pull = GPIO_NOPULL;
  HAL_GPIO_Init(GPIOK, &GPIO_InitStruct);

  /*Configure GPIO pin : SPDIF_RX_Pin */
  GPIO_InitStruct.Pin = SPDIF_RX_Pin;
  GPIO_InitStruct.Mode = GPIO_MODE_AF_PP;
  GPIO_InitStruct.Pull = GPIO_NOPULL;
  GPIO_InitStruct.Speed = GPIO_SPEED_FREQ_LOW;
  GPIO_InitStruct.Alternate = GPIO_AF7_SPDIFRX;
  HAL_GPIO_Init(SPDIF_RX_GPIO_Port, &GPIO_InitStruct);

  /*Configure GPIO pins : uSD_D1_Pin uSD_D0_Pin */
  GPIO_InitStruct.Pin = uSD_D1_Pin|uSD_D0_Pin;
  GPIO_InitStruct.Mode = GPIO_MODE_AF_PP;
  GPIO_InitStruct.Pull = GPIO_NOPULL;
  GPIO_InitStruct.Speed = GPIO_SPEED_FREQ_VERY_HIGH;
  GPIO_InitStruct.Alternate = GPIO_AF11_SDMMC2;
  HAL_GPIO_Init(GPIOG, &GPIO_InitStruct);

  /*Configure GPIO pins : RMII_RXER_Pin OTG_FS_OverCurrent_Pin */
  GPIO_InitStruct.Pin = RMII_RXER_Pin|OTG_FS_OverCurrent_Pin;
  GPIO_InitStruct.Mode = GPIO_MODE_INPUT;
  GPIO_InitStruct.Pull = GPIO_NOPULL;
  HAL_GPIO_Init(GPIOD, &GPIO_InitStruct);

  /*Configure GPIO pin : SPI2_NSS_Pin */
  GPIO_InitStruct.Pin = SPI2_NSS_Pin;
  GPIO_InitStruct.Mode = GPIO_MODE_AF_PP;
  GPIO_InitStruct.Pull = GPIO_NOPULL;
  GPIO_InitStruct.Speed = GPIO_SPEED_FREQ_VERY_HIGH;
  GPIO_InitStruct.Alternate = GPIO_AF5_SPI2;
  HAL_GPIO_Init(SPI2_NSS_GPIO_Port, &GPIO_InitStruct);

  /*Configure GPIO pin : WIFI_TX_Pin */
  GPIO_InitStruct.Pin = WIFI_TX_Pin;
  GPIO_InitStruct.Mode = GPIO_MODE_AF_PP;
  GPIO_InitStruct.Pull = GPIO_NOPULL;
  GPIO_InitStruct.Speed = GPIO_SPEED_FREQ_VERY_HIGH;
  GPIO_InitStruct.Alternate = GPIO_AF8_UART5;
  HAL_GPIO_Init(WIFI_TX_GPIO_Port, &GPIO_InitStruct);

  /*Configure GPIO pin : ULPI_DIR_Pin */
  GPIO_InitStruct.Pin = ULPI_DIR_Pin;
  GPIO_InitStruct.Mode = GPIO_MODE_AF_PP;
  GPIO_InitStruct.Pull = GPIO_NOPULL;
  GPIO_InitStruct.Speed = GPIO_SPEED_FREQ_VERY_HIGH;
  GPIO_InitStruct.Alternate = GPIO_AF10_OTG_HS;
  HAL_GPIO_Init(ULPI_DIR_GPIO_Port, &GPIO_InitStruct);

  /*Configure GPIO pin : CEC_CLK_Pin */
  GPIO_InitStruct.Pin = CEC_CLK_Pin;
  GPIO_InitStruct.Mode = GPIO_MODE_AF_PP;
  GPIO_InitStruct.Pull = GPIO_NOPULL;
  GPIO_InitStruct.Speed = GPIO_SPEED_FREQ_LOW;
  GPIO_InitStruct.Alternate = GPIO_AF0_MCO;
  HAL_GPIO_Init(CEC_CLK_GPIO_Port, &GPIO_InitStruct);

  /*Configure GPIO pin : LCD_INT_Pin */
  GPIO_InitStruct.Pin = LCD_INT_Pin;
  GPIO_InitStruct.Mode = GPIO_MODE_EVT_RISING;
  GPIO_InitStruct.Pull = GPIO_NOPULL;
  HAL_GPIO_Init(LCD_INT_GPIO_Port, &GPIO_InitStruct);

  /*Configure GPIO pins : ARD_D0_RX_Pin ARDUINO_TX_D1_Pin */
  GPIO_InitStruct.Pin = ARD_D0_RX_Pin|ARDUINO_TX_D1_Pin;
  GPIO_InitStruct.Mode = GPIO_MODE_AF_PP;
  GPIO_InitStruct.Pull = GPIO_NOPULL;
  GPIO_InitStruct.Speed = GPIO_SPEED_FREQ_VERY_HIGH;
  GPIO_InitStruct.Alternate = GPIO_AF8_USART6;
  HAL_GPIO_Init(GPIOC, &GPIO_InitStruct);

  /*Configure GPIO pin : ULPI_NXT_Pin */
  GPIO_InitStruct.Pin = ULPI_NXT_Pin;
  GPIO_InitStruct.Mode = GPIO_MODE_AF_PP;
  GPIO_InitStruct.Pull = GPIO_NOPULL;
  GPIO_InitStruct.Speed = GPIO_SPEED_FREQ_VERY_HIGH;
  GPIO_InitStruct.Alternate = GPIO_AF10_OTG_HS;
  HAL_GPIO_Init(ULPI_NXT_GPIO_Port, &GPIO_InitStruct);

  /*Configure GPIO pins : EXT_SDA_Pin EXT_SCL_Pin */
  GPIO_InitStruct.Pin = EXT_SDA_Pin|EXT_SCL_Pin;
  GPIO_InitStruct.Mode = GPIO_MODE_INPUT;
  GPIO_InitStruct.Pull = GPIO_NOPULL;
  HAL_GPIO_Init(GPIOG, &GPIO_InitStruct);

  /*Configure GPIO pin : ARD_D6_PWM_Pin */
  GPIO_InitStruct.Pin = ARD_D6_PWM_Pin;
  GPIO_InitStruct.Mode = GPIO_MODE_AF_PP;
  GPIO_InitStruct.Pull = GPIO_NOPULL;
  GPIO_InitStruct.Speed = GPIO_SPEED_FREQ_LOW;
  GPIO_InitStruct.Alternate = GPIO_AF3_TIM11;
  HAL_GPIO_Init(ARD_D6_PWM_GPIO_Port, &GPIO_InitStruct);

  /*Configure GPIO pin : ARD_D3_PWM_Pin */
  GPIO_InitStruct.Pin = ARD_D3_PWM_Pin;
  GPIO_InitStruct.Mode = GPIO_MODE_AF_PP;
  GPIO_InitStruct.Pull = GPIO_NOPULL;
  GPIO_InitStruct.Speed = GPIO_SPEED_FREQ_LOW;
  GPIO_InitStruct.Alternate = GPIO_AF3_TIM10;
  HAL_GPIO_Init(ARD_D3_PWM_GPIO_Port, &GPIO_InitStruct);

  /*Configure GPIO pins : ARDUINO_A1_Pin ARDUINO_A2_Pin ARDUINO_A3_Pin */
  GPIO_InitStruct.Pin = ARDUINO_A1_Pin|ARDUINO_A2_Pin|ARDUINO_A3_Pin;
  GPIO_InitStruct.Mode = GPIO_MODE_ANALOG;
  GPIO_InitStruct.Pull = GPIO_NOPULL;
  HAL_GPIO_Init(GPIOF, &GPIO_InitStruct);

  /*Configure GPIO pin : ULPI_STP_Pin */
  GPIO_InitStruct.Pin = ULPI_STP_Pin;
  GPIO_InitStruct.Mode = GPIO_MODE_AF_PP;
  GPIO_InitStruct.Pull = GPIO_NOPULL;
  GPIO_InitStruct.Speed = GPIO_SPEED_FREQ_VERY_HIGH;
  GPIO_InitStruct.Alternate = GPIO_AF10_OTG_HS;
  HAL_GPIO_Init(ULPI_STP_GPIO_Port, &GPIO_InitStruct);

  /*Configure GPIO pins : RMII_MDC_Pin RMII_RXD0_Pin RMII_RXD1_Pin */
  GPIO_InitStruct.Pin = RMII_MDC_Pin|RMII_RXD0_Pin|RMII_RXD1_Pin;
  GPIO_InitStruct.Mode = GPIO_MODE_AF_PP;
  GPIO_InitStruct.Pull = GPIO_NOPULL;
  GPIO_InitStruct.Speed = GPIO_SPEED_FREQ_VERY_HIGH;
  GPIO_InitStruct.Alternate = GPIO_AF11_ETH;
  HAL_GPIO_Init(GPIOC, &GPIO_InitStruct);

  /*Configure GPIO pin : ARD_A2_Pin */
  GPIO_InitStruct.Pin = ARD_A2_Pin;
  GPIO_InitStruct.Mode = GPIO_MODE_ANALOG;
  GPIO_InitStruct.Pull = GPIO_NOPULL;
  HAL_GPIO_Init(ARD_A2_GPIO_Port, &GPIO_InitStruct);

  /*Configure GPIO pins : RMII_REF_CLK_Pin RMII_MDIO_Pin RMII_CRS_DV_Pin */
  GPIO_InitStruct.Pin = RMII_REF_CLK_Pin|RMII_MDIO_Pin|RMII_CRS_DV_Pin;
  GPIO_InitStruct.Mode = GPIO_MODE_AF_PP;
  GPIO_InitStruct.Pull = GPIO_NOPULL;
  GPIO_InitStruct.Speed = GPIO_SPEED_FREQ_VERY_HIGH;
  GPIO_InitStruct.Alternate = GPIO_AF11_ETH;
  HAL_GPIO_Init(GPIOA, &GPIO_InitStruct);

  /*Configure GPIO pin : B_USER_Pin */
  GPIO_InitStruct.Pin = B_USER_Pin;
  GPIO_InitStruct.Mode = GPIO_MODE_IT_RISING;
  GPIO_InitStruct.Pull = GPIO_NOPULL;
  HAL_GPIO_Init(B_USER_GPIO_Port, &GPIO_InitStruct);

  /*Configure GPIO pins : ARD_A1_Pin ARD_A0_Pin */
  GPIO_InitStruct.Pin = ARD_A1_Pin|ARD_A0_Pin;
  GPIO_InitStruct.Mode = GPIO_MODE_ANALOG;
  GPIO_InitStruct.Pull = GPIO_NOPULL;
  HAL_GPIO_Init(GPIOA, &GPIO_InitStruct);

  /*Configure GPIO pin : SPDIF_TX_Pin */
  GPIO_InitStruct.Pin = SPDIF_TX_Pin;
  GPIO_InitStruct.Mode = GPIO_MODE_AF_PP;
  GPIO_InitStruct.Pull = GPIO_NOPULL;
  GPIO_InitStruct.Speed = GPIO_SPEED_FREQ_LOW;
  GPIO_InitStruct.Alternate = GPIO_AF10_SAI2;
  HAL_GPIO_Init(SPDIF_TX_GPIO_Port, &GPIO_InitStruct);

  /*Configure GPIO pin : PH7 */
  GPIO_InitStruct.Pin = GPIO_PIN_7;
  GPIO_InitStruct.Mode = GPIO_MODE_INPUT;
  GPIO_InitStruct.Pull = GPIO_NOPULL;
  HAL_GPIO_Init(GPIOH, &GPIO_InitStruct);

  /*Configure GPIO pins : ULPI_CLK_Pin ULPI_D0_Pin */
  GPIO_InitStruct.Pin = ULPI_CLK_Pin|ULPI_D0_Pin;
  GPIO_InitStruct.Mode = GPIO_MODE_AF_PP;
  GPIO_InitStruct.Pull = GPIO_NOPULL;
  GPIO_InitStruct.Speed = GPIO_SPEED_FREQ_VERY_HIGH;
  GPIO_InitStruct.Alternate = GPIO_AF10_OTG_HS;
  HAL_GPIO_Init(GPIOA, &GPIO_InitStruct);

  /*Configure GPIO pins : ARDUINO_MISO_D12_Pin ARDUINO_MOSI_PWM_D11_Pin */
  GPIO_InitStruct.Pin = ARDUINO_MISO_D12_Pin|ARDUINO_MOSI_PWM_D11_Pin;
  GPIO_InitStruct.Mode = GPIO_MODE_AF_PP;
  GPIO_InitStruct.Pull = GPIO_NOPULL;
  GPIO_InitStruct.Speed = GPIO_SPEED_FREQ_LOW;
  GPIO_InitStruct.Alternate = GPIO_AF5_SPI2;
  HAL_GPIO_Init(GPIOB, &GPIO_InitStruct);

}

/* USER CODE BEGIN 4 */

// ----------------------------------------------------------------------------
// Implementation of the OTM8009A I/O functions for the DSI interface
// ----------------------------------------------------------------------------

// Forward the OTM8009A driver's command tables to DSI virtual channel 0.
void DSI_IO_WriteCmd(uint32_t NbrParams, uint8_t *pParams)
{
  HAL_StatusTypeDef status;

  if (NbrParams <= 1U) {
    // This driver stores short writes as {command, parameter}, even for count 0.
    status = HAL_DSI_ShortWrite(
        &hdsi,
        0U,
        DSI_DCS_SHORT_PKT_WRITE_P1,
        pParams[0],
        pParams[1]
    );
  }
  else {
    // Long-write tables contain the parameter bytes followed by the command.
    status = HAL_DSI_LongWrite(
        &hdsi,
        0U,
        DSI_DCS_LONG_PKT_WRITE,
        NbrParams,
        pParams[NbrParams],
        pParams
    );
  }

  if (status != HAL_OK)
  {
    Error_Handler();
  }
}

// Read a DCS register on virtual channel 0; return 0 on success, 1 on failure.
int32_t DSI_IO_ReadCmd(uint32_t Reg, uint8_t *pData, uint32_t Size)
{
  if ((pData == NULL) || (Size == 0U)) {
    return 1;
  }

  // DCS reads use Reg directly and do not need a generic parameter table.
  if (HAL_DSI_Read(&hdsi, 0U, pData, Size, DSI_DCS_SHORT_PKT_READ,
                   Reg, NULL) != HAL_OK) {
    return 1;
  }

  return 0;
}

// Delay in milliseconds, usable during startup and from a running RTOS task.
void OTM8009A_IO_Delay(uint32_t Delay) {
  if (Delay == 0U) {
    return;
  }

  if (osKernelGetState() == osKernelRunning) {
    const uint64_t ticks =
        (((uint64_t)Delay * osKernelGetTickFreq() + 999U) / 1000U) + 1U;

    if(ticks >= osWaitForever) {
    	Error_Handler();
    }

    const osStatus_t delay_res = osDelay((uint32_t)ticks);
    (void) delay_res;
  }
  else {
    // Startup, or scheduler locked: use the independent TIM6 HAL time base.
    HAL_Delay(Delay);
  }
}

/* USER CODE END 4 */

void StartDefaultTask(void *argument)
{
  /* USER CODE BEGIN 5 */
  /* Infinite loop */
  for(;;)
  {

    osDelay(10000);
  }
  /* USER CODE END 5 */
}

void start_audio_producer(void *argument)
{
  /* USER CODE BEGIN start_audio_producer */
  static volatile int sai_init_status;

  sai_init_status = sai_init(&hsai_BlockA1, &hdma_sai1_a, &hi2c4);
  if (sai_init_status != 0) {
    Error_Handler();
  }

#if SAI_TEST_TONE_ONLY
  if (sai_test_tone_start_1khz() != 0) {
    Error_Handler();
  }

  for (;;) {
    osDelay(1000U);
  }
#else
  const int ret = exec_pdm_task(&hdfsdm1_filter0);
  (void) ret;
#endif
  /* USER CODE END start_audio_producer */
}

void start_uart_handler(void *argument)
{
  /* USER CODE BEGIN start_uart_handler */
  (void) exec_uart_task(&huart1);
  /* USER CODE END start_uart_handler */
}

void start_audio_filter(void *argument)
{
  /* USER CODE BEGIN start_audio_filter */

  static float xcorr_out_f[AUDIO_LEN];
  static int16_t xcorr_out_s16[AUDIO_LEN];

  /* Infinite loop */
  for(;;)
  {
    osDelay(1);
    const int filter_res = pop_audio_buffer();
    if(filter_res == 0) {
    	// no error
    	get_xcorr_buffer_48kHz(xcorr_out_f);

    	for(int i = 0; i < AUDIO_LEN; i ++) {
    		xcorr_out_s16[i] = (int16_t)xcorr_out_f[i];
    	}

    	send_uart_int16(xcorr_out_s16, AUDIO_LEN);
    }
  }
  /* USER CODE END start_audio_filter */
}

void start_display_control(void *argument)
{
  /* USER CODE BEGIN start_display_control */
  display_init(&hltdc, &hdsi);
  g_display_stack_min_free_bytes = osThreadGetStackSpace(display_controlHandle);

  /* Infinite loop */
  static FT6X06_MultiTouch_State_t ts_state;
  uint8_t data = 0U;
  for(;;)
  {

    FT6X06_GetMultiTouchState(&ft6x06_object, &ts_state);
    data = (uint8_t)ts_state.TouchDetected;
    osDelay(100);
    display_cyclic_exec_funciton(data);
    g_display_stack_min_free_bytes = osThreadGetStackSpace(display_controlHandle);
  }
  /* USER CODE END start_display_control */
}

 /* MPU Configuration */

void MPU_Config(void)
{
  MPU_Region_InitTypeDef MPU_InitStruct = {0};

  /* Disables the MPU */
  HAL_MPU_Disable();

  /** Initializes and configures the Region and the memory to be protected
  */
  MPU_InitStruct.Enable = MPU_REGION_ENABLE;
  MPU_InitStruct.Number = MPU_REGION_NUMBER0;
  MPU_InitStruct.BaseAddress = 0xC0000000;
  MPU_InitStruct.Size = MPU_REGION_SIZE_2MB;
  MPU_InitStruct.SubRegionDisable = 0x0;
  MPU_InitStruct.TypeExtField = MPU_TEX_LEVEL0;
  MPU_InitStruct.AccessPermission = MPU_REGION_FULL_ACCESS;
  MPU_InitStruct.DisableExec = MPU_INSTRUCTION_ACCESS_DISABLE;
  MPU_InitStruct.IsShareable = MPU_ACCESS_NOT_SHAREABLE;
  MPU_InitStruct.IsCacheable = MPU_ACCESS_NOT_CACHEABLE;
  MPU_InitStruct.IsBufferable = MPU_ACCESS_NOT_BUFFERABLE;

  HAL_MPU_ConfigRegion(&MPU_InitStruct);
  /* Enables the MPU */
  HAL_MPU_Enable(MPU_HFNMI_PRIVDEF);

}

void HAL_TIM_PeriodElapsedCallback(TIM_HandleTypeDef *htim)
{
  if (htim->Instance == TIM6)
  {
    HAL_IncTick();
  }
}

void Error_Handler(void)
{
  __disable_irq();
  while (1)
  {
  }
}

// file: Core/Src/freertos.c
/* USER CODE BEGIN Header */
/**
  ******************************************************************************
  * File Name          : freertos.c
  * Description        : Code for freertos applications
  ******************************************************************************
  * @attention
  *
  * Copyright (c) 2026 STMicroelectronics.
  * All rights reserved.
  *
  * This software is licensed under terms that can be found in the LICENSE file
  * in the root directory of this software component.
  * If no LICENSE file comes with this software, it is provided AS-IS.
  *
  ******************************************************************************
  */
/* USER CODE END Header */

#include "FreeRTOS.h"
#include "task.h"
#include "main.h"

/* USER CODE BEGIN Variables */

/* Failure reason: 1 = task stack overflow, 2 = FreeRTOS heap exhausted. */
volatile uint32_t g_rtos_failure_reason;
TaskHandle_t volatile g_rtos_failed_task;
const char * volatile g_rtos_failed_task_name;

/* USER CODE END Variables */

/* USER CODE BEGIN Application */

void vApplicationStackOverflowHook(TaskHandle_t task, char *task_name)
{
  taskDISABLE_INTERRUPTS();
  g_rtos_failed_task = task;
  g_rtos_failed_task_name = task_name;
  g_rtos_failure_reason = 1U;
  /* The task name pointer may refer to corrupted memory; do not dereference it. */
  for (;;) { __NOP(); }
}

void vApplicationMallocFailedHook(void)
{
  taskDISABLE_INTERRUPTS();
  g_rtos_failure_reason = 2U;
  for (;;) { __NOP(); }
}

/* USER CODE END Application */
